VERSION ""

NS_ :

BS_:

BU_: GW TBOX VCU IPU DCDC OBC TESTER BMSH Vector_XXX
VAL_TABLE_ ABS_VehicleSpeedInvalid 1 "invalid" 0 "valid" ;
VAL_TABLE_ VCU_ePTReady 1 "PTReady  Active" 0 "PTReady Not Active" ;

BO_ 3221225472 VECTOR__INDEPENDENT_SIG_MSG: 0 Vector__XXX
 SG_ DCDC_InCurOver : 0|1@0+ (1,0) [0|1] "-" Vector__XXX
 SG_ DCDC_DataStorageFault : 0|1@0+ (1,0) [0|1] "-" Vector__XXX
 SG_ DCDC_InternalComFault : 0|1@0+ (1,0) [0|1] "-" Vector__XXX
 SG_ DCDC_BatVoltFault : 0|1@0+ (1,0) [0|1] "-" Vector__XXX
 SG_ DCDC_OutInversed : 0|1@0+ (1,0) [0|1] "-" Vector__XXX
 SG_ IPU_IPUTempSensorFault : 0|1@0+ (1,0) [0|1] "-" Vector__XXX
 SG_ IPU_5VUnderVoltageAlarm : 0|1@0+ (1,0) [0|1] "-" Vector__XXX
 SG_ IPU_5VOverVoltageAlarm : 0|1@0+ (1,0) [0|1] "-" Vector__XXX
 SG_ IPU_HVShortCircuit : 0|1@0+ (1,0) [0|1] "-" Vector__XXX
 SG_ IPU_IPUDrvModuleUV : 0|1@0+ (1,0) [0|1] "-" Vector__XXX
 SG_ IPU_MotModuleFault : 0|1@0+ (1,0) [0|1] "-" Vector__XXX

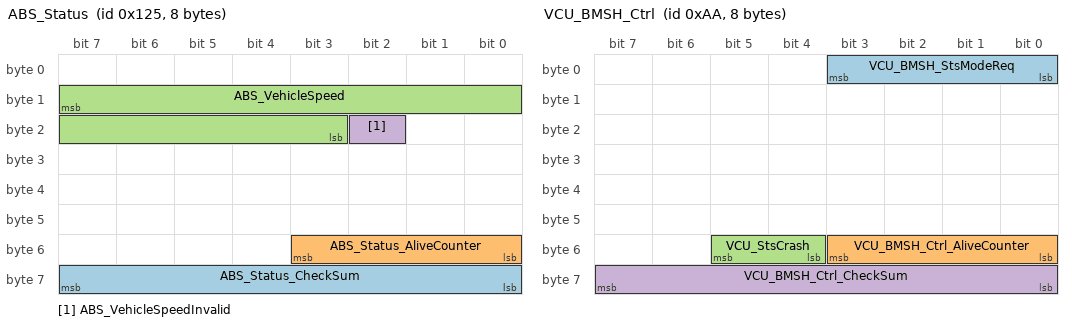
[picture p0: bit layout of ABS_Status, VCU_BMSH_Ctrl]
BO_ 293 ABS_Status: 8 GW
 SG_ ABS_Status_CheckSum : 63|8@0+ (1,0) [0|0] ""  BMSH,DCDC,IPU,OBC
 SG_ ABS_Status_AliveCounter : 51|4@0+ (1,0) [0|0] ""  BMSH,DCDC,IPU,OBC
 SG_ ABS_VehicleSpeed : 15|13@0- (0.05625,0) [0|460.63125] "kph"  BMSH,DCDC,IPU,OBC
 SG_ ABS_VehicleSpeedInvalid : 18|1@0- (1,0) [0|1] ""  BMSH,DCDC,IPU,OBC

BO_ 354 VCU_Ctrl: 8 GW
 SG_ VCU_ePTReady : 31|1@0+ (1,0) [0|1] "" Vector__XXX

BO_ 170 VCU_BMSH_Ctrl: 8 VCU
 SG_ VCU_BMSH_StsModeReq : 3|4@0+ (1,0) [0|15] "-"  BMSH
 SG_ VCU_BMSH_Ctrl_AliveCounter : 51|4@0+ (1,0) [0|15] "-"  BMSH
 SG_ VCU_StsCrash : 53|2@0+ (1,0) [0|1] "-"  BMSH
 SG_ VCU_BMSH_Ctrl_CheckSum : 63|8@0+ (1,0) [0|255] "-"  BMSH

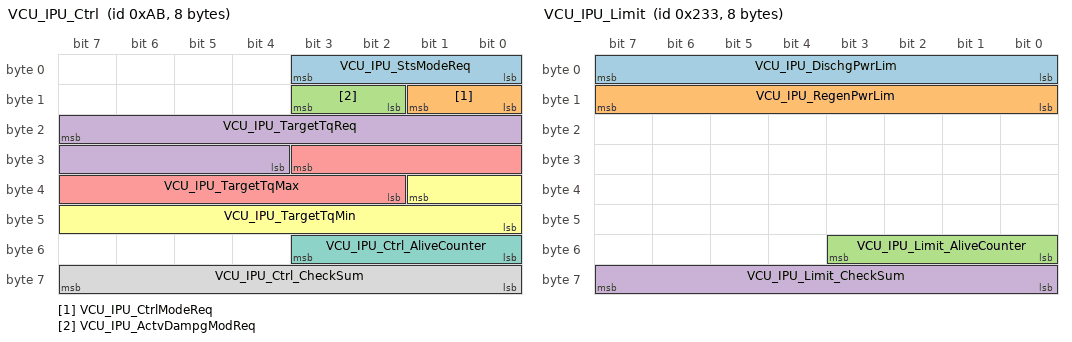
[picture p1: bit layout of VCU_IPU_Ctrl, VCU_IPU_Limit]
BO_ 171 VCU_IPU_Ctrl: 8 VCU
 SG_ VCU_IPU_StsModeReq : 3|4@0+ (1,0) [0|15] "-"  IPU
 SG_ VCU_IPU_CtrlModeReq : 9|2@0+ (1,0) [0|3] "-"  IPU
 SG_ VCU_IPU_ActvDampgModReq : 11|2@0+ (1,0) [0|3] "-"  IPU
 SG_ VCU_IPU_TargetTqReq : 23|12@0+ (0.5,-500) [-500|500] "Nm"  IPU
 SG_ VCU_IPU_TargetTqMax : 27|10@0+ (1,0) [0|500] "Nm"  IPU
 SG_ VCU_IPU_TargetTqMin : 33|10@0+ (1,-500) [-500|0] "Nm"  IPU
 SG_ VCU_IPU_Ctrl_AliveCounter : 51|4@0+ (1,0) [0|15] "-"  IPU
 SG_ VCU_IPU_Ctrl_CheckSum : 63|8@0+ (1,0) [0|255] "-"  IPU

BO_ 563 VCU_IPU_Limit: 8 VCU
 SG_ VCU_IPU_DischgPwrLim : 7|8@0+ (1,0) [0|250] "kW"  IPU
 SG_ VCU_IPU_RegenPwrLim : 15|8@0+ (1,0) [0|250] "kW"  IPU
 SG_ VCU_IPU_Limit_AliveCounter : 51|4@0+ (1,0) [0|15] "-"  IPU
 SG_ VCU_IPU_Limit_CheckSum : 63|8@0+ (1,0) [0|255] "-"  IPU

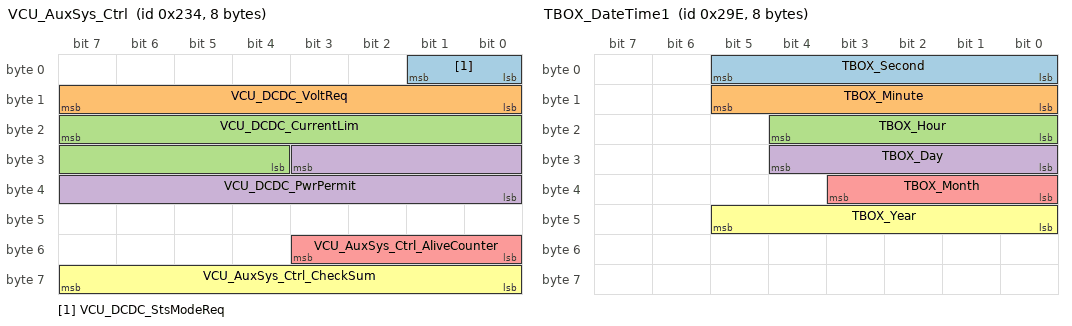
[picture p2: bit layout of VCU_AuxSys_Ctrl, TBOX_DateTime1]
BO_ 564 VCU_AuxSys_Ctrl: 8 VCU
 SG_ VCU_DCDC_StsModeReq : 1|2@0+ (1,0) [0|3] "-"  DCDC
 SG_ VCU_DCDC_VoltReq : 15|8@0+ (0.1,0) [0|25] "V"  DCDC
 SG_ VCU_DCDC_CurrentLim : 23|12@0+ (0.1,0) [0|250] "A"  DCDC
 SG_ VCU_DCDC_PwrPermit : 27|12@0+ (1,0) [0|3000] "Kw"  DCDC
 SG_ VCU_AuxSys_Ctrl_AliveCounter : 51|4@0+ (1,0) [0|15] "-"  DCDC
 SG_ VCU_AuxSys_Ctrl_CheckSum : 63|8@0+ (1,0) [0|255] "-"  DCDC

BO_ 569 VCU_Fault: 8 VCU
 SG_ VCU_ChgFaultReq : 3|4@0+ (1,0) [0|15] "-"  Vector_XXX
 SG_ VCU_DischgFaultReq : 7|4@0+ (1,0) [0|15] "-"  Vector_XXX

BO_ 257 PEPS_IMMOCode: 8 GW
 SG_ PEPS_IMMOCode : 7|64@0+ (1,0) [0|65535] "bit"  IPU

BO_ 482 PEPS_Message_Sts: 8 GW
 SG_ PEPS_PowerModeValidity : 1|2@0+ (1,0) [0|3] "bit"  BMSH,IPU
 SG_ PEPS_PowerMode : 4|3@0+ (1,0) [0|7] "bit"  BMSH,IPU

BO_ 645 BCM_LDoorWindowState: 8 GW
 SG_ BCM_DoorLockStatusDrv : 37|2@0+ (1,0) [0|3] "bit"  OBC

BO_ 670 TBOX_DateTime1: 8 TBOX
 SG_ TBOX_Second : 5|6@0+ (1,0) [0|59] "s"  BMSH
 SG_ TBOX_Minute : 13|6@0+ (1,0) [0|59] "m"  BMSH
 SG_ TBOX_Hour : 20|5@0+ (1,0) [0|23] "h"  BMSH
 SG_ TBOX_Day : 28|5@0+ (1,0) [1|31] "d"  BMSH
 SG_ TBOX_Month : 35|4@0+ (1,0) [1|12] "m"  BMSH
 SG_ TBOX_Year : 45|6@0+ (1,0) [0|63] "y"  BMSH

BO_ 1009 IPK_TotalOdometer: 8 GW
 SG_ IPK_IPKTotalOdometer : 7|24@0+ (0.1,0) [0|999999] "KM"  BMSH

BO_ 185 BMSH_Status: 8 BMSH
 SG_ BMSH_VCU_DischgFaultReq : 3|4@0+ (1,0) [0|15] "-"  VCU
 SG_ BMSH_StsDischgFault : 7|4@0+ (1,0) [0|15] "-"  Vector_XXX
 SG_ BMSH_VCU_ChgFaultReq : 11|4@0+ (1,0) [0|15] "-"  VCU
 SG_ BMSH_StsChgFault : 15|4@0+ (1,0) [0|15] "-"  Vector_XXX
 SG_ BMSH_StsCellBalance : 17|2@0+ (1,0) [0|3] "-"  TBOX
 SG_ BMSH_StsPrecharge : 19|2@0+ (1,0) [0|3] "-"  VCU
 SG_ BMSH_StsMode : 23|4@0+ (1,0) [0|15] "-"  IPU,VCU
 SG_ BMSH_VCU_StsMainHVIL : 25|2@0+ (1,0) [0|3] "-"  VCU
 SG_ BMSH_StsInsulation : 27|2@0+ (1,0) [0|3] "-"  VCU,TBOX
 SG_ BMSH_StsCC2 : 29|2@0+ (1,0) [0|3] "-"  VCU
 SG_ BMSH_StsCC1 : 31|2@0+ (1,0) [0|3] "-"  VCU
 SG_ BMSH_StsMainNegtiveRelay : 33|2@0+ (1,0) [0|3] "-"  VCU
 SG_ BMSH_StsMainPositiveRelay : 35|2@0+ (1,0) [0|3] "-"  IPU,VCU
 SG_ BMSH_VCU_StsDCChgRelay : 45|2@0+ (1,0) [0|3] "-"  VCU
 SG_ BMSH_VCU_StsPreChgRelay : 47|2@0+ (1,0) [0|3] "-"  VCU
 SG_ BMSH_Status_AliveCounter : 51|4@0+ (1,0) [0|15] "-"  IPU,VCU
 SG_ BMSH_VCU_Crash : 53|1@0+ (1,0) [0|1] "-"  VCU
 SG_ BMSH_Status_CheckSum : 63|8@0+ (1,0) [0|255] "-"  IPU,VCU

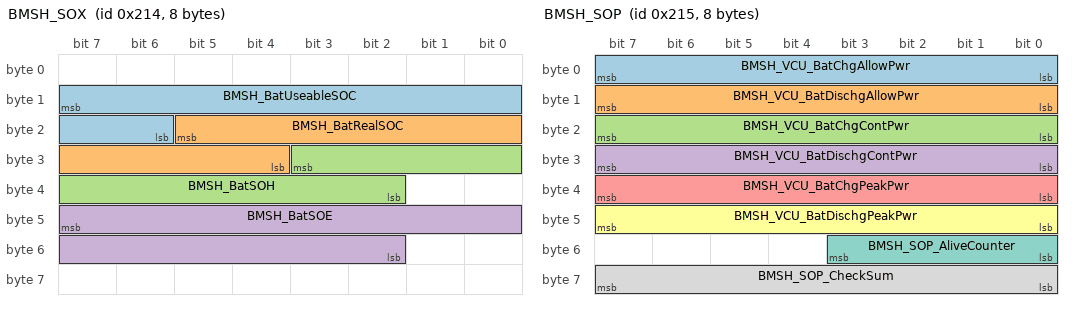
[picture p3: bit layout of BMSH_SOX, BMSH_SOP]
BO_ 532 BMSH_SOX: 8 BMSH
 SG_ BMSH_BatUseableSOC : 15|10@0+ (0.1,0) [0|100] "%"  VCU,TBOX
 SG_ BMSH_BatRealSOC : 21|10@0+ (0.1,0) [0|100] "%"  Vector_XXX
 SG_ BMSH_BatSOH : 27|10@0+ (0.1,0) [0|100] "%"  TBOX
 SG_ BMSH_BatSOE : 47|14@0+ (0.1,0) [0|999.9] "kWh"  VCU,TBOX

BO_ 533 BMSH_SOP: 8 BMSH
 SG_ BMSH_VCU_BatChgAllowPwr : 7|8@0+ (1,0) [0|250] "kW"  VCU
 SG_ BMSH_VCU_BatDischgAllowPwr : 15|8@0+ (1,0) [0|250] "kW"  VCU
 SG_ BMSH_VCU_BatChgContPwr : 23|8@0+ (1,0) [0|250] "kW"  VCU
 SG_ BMSH_VCU_BatDischgContPwr : 31|8@0+ (1,0) [0|250] "kW"  VCU
 SG_ BMSH_VCU_BatChgPeakPwr : 39|8@0+ (1,0) [0|250] "kW"  VCU
 SG_ BMSH_VCU_BatDischgPeakPwr : 47|8@0+ (1,0) [0|250] "kW"  VCU
 SG_ BMSH_SOP_AliveCounter : 51|4@0+ (1,0) [0|15] "-"  VCU
 SG_ BMSH_SOP_CheckSum : 63|8@0+ (1,0) [0|255] "-"  VCU

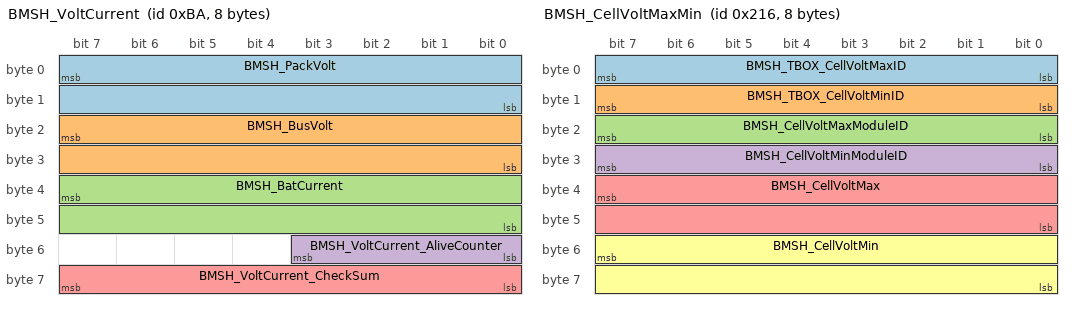
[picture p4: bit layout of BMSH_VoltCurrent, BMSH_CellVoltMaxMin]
BO_ 186 BMSH_VoltCurrent: 8 BMSH
 SG_ BMSH_PackVolt : 7|16@0+ (0.1,0) [0|1000] "V"  IPU,VCU,TBOX
 SG_ BMSH_BusVolt : 23|16@0+ (0.1,0) [0|1000] "V"  VCU
 SG_ BMSH_BatCurrent : 39|16@0+ (0.1,-1000) [-1000|1000] "A"  VCU,TBOX
 SG_ BMSH_VoltCurrent_AliveCounter : 51|4@0+ (1,0) [0|15] "-"  IPU,VCU
 SG_ BMSH_VoltCurrent_CheckSum : 63|8@0+ (1,0) [0|255] "-"  IPU,VCU

BO_ 534 BMSH_CellVoltMaxMin: 8 BMSH
 SG_ BMSH_TBOX_CellVoltMaxID : 7|8@0+ (1,0) [0|250] "-"  TBOX
 SG_ BMSH_TBOX_CellVoltMinID : 15|8@0+ (1,0) [0|250] "-"  TBOX
 SG_ BMSH_CellVoltMaxModuleID : 23|8@0+ (1,0) [0|250] "-"  TBOX
 SG_ BMSH_CellVoltMinModuleID : 31|8@0+ (1,0) [0|250] "-"  TBOX
 SG_ BMSH_CellVoltMax : 39|16@0+ (0.001,0) [0|5] "V"  VCU,TBOX
 SG_ BMSH_CellVoltMin : 55|16@0+ (0.001,0) [0|5] "V"  VCU,TBOX

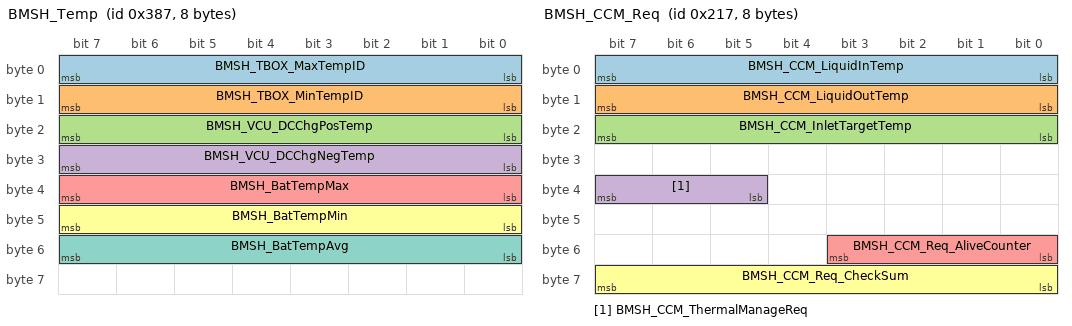
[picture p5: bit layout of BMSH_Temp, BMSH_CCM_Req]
BO_ 903 BMSH_Temp: 8 BMSH
 SG_ BMSH_TBOX_MaxTempID : 7|8@0+ (1,0) [0|250] "-"  TBOX
 SG_ BMSH_TBOX_MinTempID : 15|8@0+ (1,0) [0|250] "-"  TBOX
 SG_ BMSH_VCU_DCChgPosTemp : 23|8@0+ (1,-40) [-40|210] "℃"  VCU
 SG_ BMSH_VCU_DCChgNegTemp : 31|8@0+ (1,-40) [-40|210] "℃"  VCU
 SG_ BMSH_BatTempMax : 39|8@0+ (0.5,-40) [-40|87] "℃"  VCU,TBOX
 SG_ BMSH_BatTempMin : 47|8@0+ (0.5,-40) [-40|87] "℃"  VCU,TBOX
 SG_ BMSH_BatTempAvg : 55|8@0+ (0.5,-40) [-40|87] "℃"  OBC,VCU

BO_ 535 BMSH_CCM_Req: 8 BMSH
 SG_ BMSH_CCM_LiquidInTemp : 7|8@0+ (1,-40) [-40|255] "℃"  VCU
 SG_ BMSH_CCM_LiquidOutTemp : 15|8@0+ (1,-40) [-40|255] "℃"  VCU
 SG_ BMSH_CCM_InletTargetTemp : 23|8@0+ (1,-40) [-40|210] "℃"  VCU
 SG_ BMSH_CCM_ThermalManageReq : 39|3@0+ (1,0) [0|4] "-"  VCU
 SG_ BMSH_CCM_Req_AliveCounter : 51|4@0+ (1,0) [0|15] "-"  VCU
 SG_ BMSH_CCM_Req_CheckSum : 63|8@0+ (1,0) [0|255] "-"  VCU

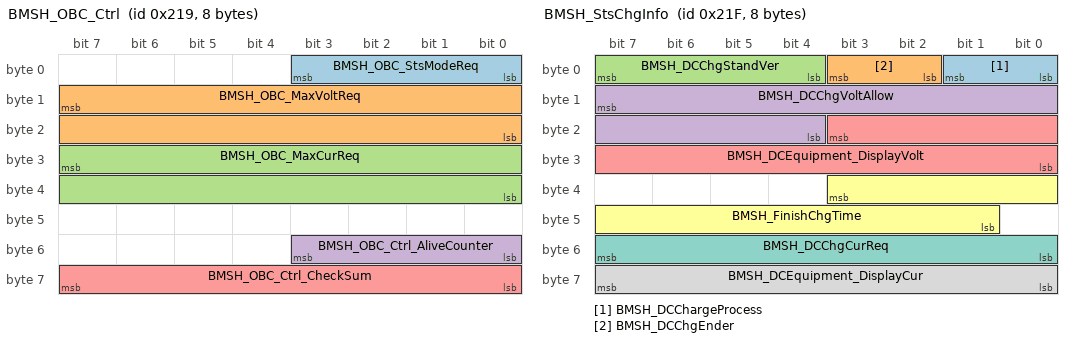
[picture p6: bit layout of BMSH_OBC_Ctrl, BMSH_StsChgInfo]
BO_ 537 BMSH_OBC_Ctrl: 8 BMSH
 SG_ BMSH_OBC_StsModeReq : 3|4@0+ (1,0) [0|15] "-"  OBC
 SG_ BMSH_OBC_MaxVoltReq : 15|16@0+ (0.1,0) [0|1000] "V"  OBC
 SG_ BMSH_OBC_MaxCurReq : 31|16@0+ (0.1,-1000) [-1000|1000] "A"  OBC
 SG_ BMSH_OBC_Ctrl_AliveCounter : 51|4@0+ (1,0) [0|15] "-"  OBC
 SG_ BMSH_OBC_Ctrl_CheckSum : 63|8@0+ (1,0) [0|255] "-"  OBC

BO_ 543 BMSH_StsChgInfo: 8 BMSH
 SG_ BMSH_DCChargeProcess : 1|2@0+ (1,0) [0|3] "-"  Vector_XXX
 SG_ BMSH_DCChgEnder : 3|2@0+ (1,0) [0|3] "-"  Vector_XXX
 SG_ BMSH_DCChgStandVer : 7|4@0+ (1,0) [0|15] "-"  Vector_XXX
 SG_ BMSH_DCChgVoltAllow : 15|12@0+ (1,0) [0|1000] "V"  Vector_XXX
 SG_ BMSH_DCEquipment_DisplayVolt : 19|12@0+ (1,0) [0|1000] "V"  Vector_XXX
 SG_ BMSH_FinishChgTime : 35|11@0+ (1,0) [0|1800] "Min"  VCU
 SG_ BMSH_DCChgCurReq : 55|8@0+ (1,0) [0|254] "A"  Vector_XXX
 SG_ BMSH_DCEquipment_DisplayCur : 63|8@0+ (1,0) [0|254] "A"  Vector_XXX

BO_ 904 BMSH_Fault: 8 BMSH
 SG_ BMSH_ChgOverCurrent : 1|2@0+ (1,0) [0|3] "-"  VCU
 SG_ BMSH_DisChgOverCurrent : 3|2@0+ (1,0) [0|3] "-"  Vector_XXX
 SG_ BMSH_CellOverVolt : 5|2@0+ (1,0) [0|3] "-"  Vector_XXX
 SG_ BMSH_CellUnderVolt : 7|2@0+ (1,0) [0|3] "-"  Vector_XXX
 SG_ BMSH_ChgOverTemp : 9|2@0+ (1,0) [0|3] "-"  Vector_XXX
 SG_ BMSH_BatUnderVolt : 11|2@0+ (1,0) [0|3] "-"  Vector_XXX
 SG_ BMSH_BatOverVolt : 13|2@0+ (1,0) [0|3] "-"  Vector_XXX
 SG_ BMSH_CellDiffVoltUniform : 15|2@0+ (1,0) [0|3] "-"  Vector_XXX
 SG_ BMSH_CellTempUniformity : 17|2@0+ (1,0) [0|3] "-"  Vector_XXX
 SG_ BMSH_DisChgUnderTemp : 19|2@0+ (1,0) [0|3] "-"  Vector_XXX
 SG_ BMSH_DisChgOverTemp : 21|2@0+ (1,0) [0|3] "-"  Vector_XXX
 SG_ BMSH_ChgUnderTemp : 23|2@0+ (1,0) [0|3] "-"  Vector_XXX
 SG_ BMSH_MainPosRelayFault : 25|2@0+ (1,0) [0|3] "-"  VCU,TBOX
 SG_ BMSH_RecoveryOverCurrent : 27|2@0+ (1,0) [0|3] "-"  Vector_XXX
 SG_ BMSH_BatUnderSOC : 29|2@0+ (1,0) [0|3] "-"  Vector_XXX
 SG_ BMSH_BatOverSOC : 31|2@0+ (1,0) [0|3] "-"  Vector_XXX
 SG_ BMSH_DCChgPlugNOverTemp : 33|2@0+ (1,0) [0|3] "-"  Vector_XXX
 SG_ BMSH_DCChgPlugPOverTemp : 35|2@0+ (1,0) [0|3] "-"  Vector_XXX
 SG_ BMSH_DCChgRelayFault : 37|2@0+ (1,0) [0|3] "-"  TBOX
 SG_ BMSH_MainNegRelayFault : 39|2@0+ (1,0) [0|3] "-"  VCU,TBOX
 SG_ BMSH_IntComFault : 40|1@0+ (1,0) [0|1] "-"  Vector_XXX
 SG_ BMSH_DisChgComFault : 41|1@0+ (1,0) [0|1] "-"  Vector_XXX
 SG_ BMSH_FastChgComFault : 42|1@0+ (1,0) [0|1] "-"  Vector_XXX
 SG_ BMSH_12VBatFault : 43|1@0+ (1,0) [0|1] "-"  Vector_XXX
 SG_ BMSH_ConnectPosOverTemp : 45|2@0+ (1,0) [0|3] "-"  VCU
 SG_ BMSH_ConnectNegOverTemp : 47|2@0+ (1,0) [0|3] "-"  VCU
 SG_ BMSH_VCUChksumFault : 50|1@0+ (1,0) [0|1] "-"  Vector_XXX
 SG_ BMSH_VCURollCountFault : 51|1@0+ (1,0) [0|1] "-"  Vector_XXX
 SG_ BMSH_OBCChksumFault : 52|1@0+ (1,0) [0|1] "-"  Vector_XXX
 SG_ BMSH_OBCRollCountFault : 53|1@0+ (1,0) [0|1] "-"  Vector_XXX
 SG_ BMSH_SelfCheckFault : 54|1@0+ (1,0) [0|1] "-"  Vector_XXX
 SG_ BMSH_DataStorageFault : 55|1@0+ (1,0) [0|1] "-"  Vector_XXX
 SG_ BMSH_FaultCode : 63|8@0+ (1,0) [0|255] "-"  Vector_XXX

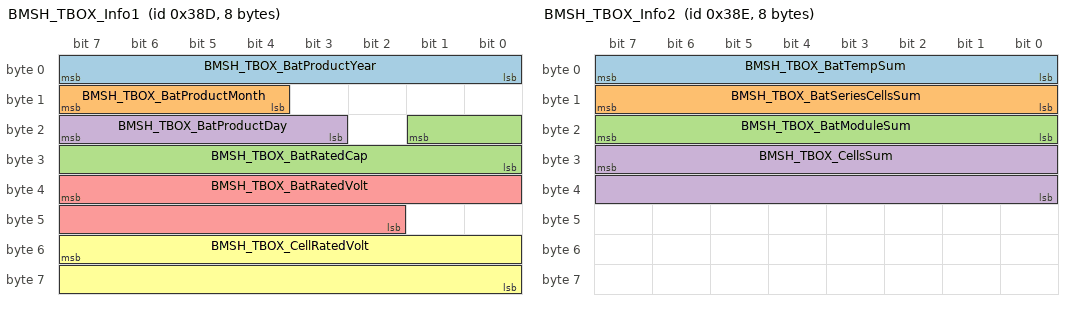
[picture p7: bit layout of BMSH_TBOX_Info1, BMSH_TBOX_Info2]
BO_ 909 BMSH_TBOX_Info1: 8 BMSH
 SG_ BMSH_TBOX_BatProductYear : 7|8@0+ (1,2000) [2000|2250] "-"  TBOX
 SG_ BMSH_TBOX_BatProductMonth : 15|4@0+ (1,0) [1|12] "-"  TBOX
 SG_ BMSH_TBOX_BatRatedCap : 17|10@0+ (0.1,0) [0|100] "kWh"  TBOX
 SG_ BMSH_TBOX_BatProductDay : 23|5@0+ (1,0) [1|31] "-"  TBOX
 SG_ BMSH_TBOX_BatRatedVolt : 39|14@0+ (0.1,0) [0|1000] "V"  TBOX
 SG_ BMSH_TBOX_CellRatedVolt : 55|16@0+ (0.001,0) [0|5] "V"  TBOX

BO_ 910 BMSH_TBOX_Info2: 8 BMSH
 SG_ BMSH_TBOX_BatTempSum : 7|8@0+ (1,0) [0|250] "-"  TBOX
 SG_ BMSH_TBOX_BatSeriesCellsSum : 15|8@0+ (1,0) [0|250] "-"  TBOX
 SG_ BMSH_TBOX_BatModuleSum : 23|8@0+ (1,0) [0|250] "-"  TBOX
 SG_ BMSH_TBOX_CellsSum : 31|16@0+ (1,0) [0|65531] "-"  TBOX

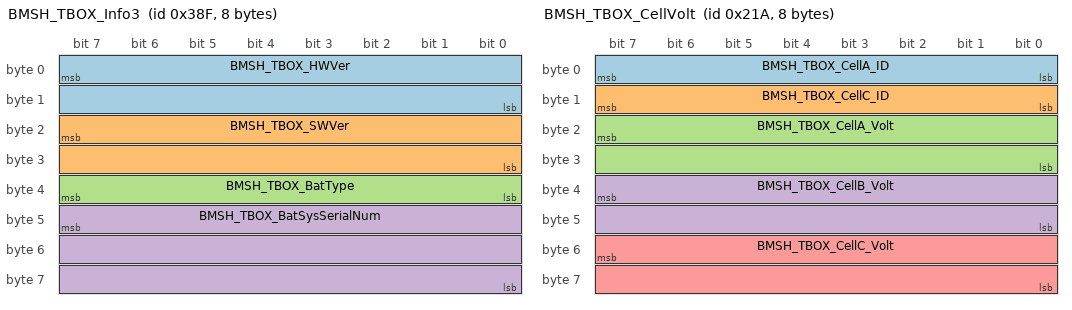
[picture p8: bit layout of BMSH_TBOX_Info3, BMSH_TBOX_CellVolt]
BO_ 911 BMSH_TBOX_Info3: 8 BMSH
 SG_ BMSH_TBOX_HWVer : 7|16@0+ (1,0) [0|65535] "-"  TBOX
 SG_ BMSH_TBOX_SWVer : 23|16@0+ (1,0) [0|65535] "-"  TBOX
 SG_ BMSH_TBOX_BatType : 39|8@0+ (1,0) [0|255] "-"  TBOX
 SG_ BMSH_TBOX_BatSysSerialNum : 47|24@0+ (1,0) [0|999999] "-"  TBOX

BO_ 538 BMSH_TBOX_CellVolt: 8 BMSH
 SG_ BMSH_TBOX_CellA_ID : 7|8@0+ (1,0) [0|210] "-"  TBOX
 SG_ BMSH_TBOX_CellC_ID : 15|8@0+ (1,0) [0|210] "-"  TBOX
 SG_ BMSH_TBOX_CellA_Volt : 23|16@0+ (0.001,0) [0|5] "V"  TBOX
 SG_ BMSH_TBOX_CellB_Volt : 39|16@0+ (0.001,0) [0|5] "V"  TBOX
 SG_ BMSH_TBOX_CellC_Volt : 55|16@0+ (0.001,0) [0|5] "V"  TBOX

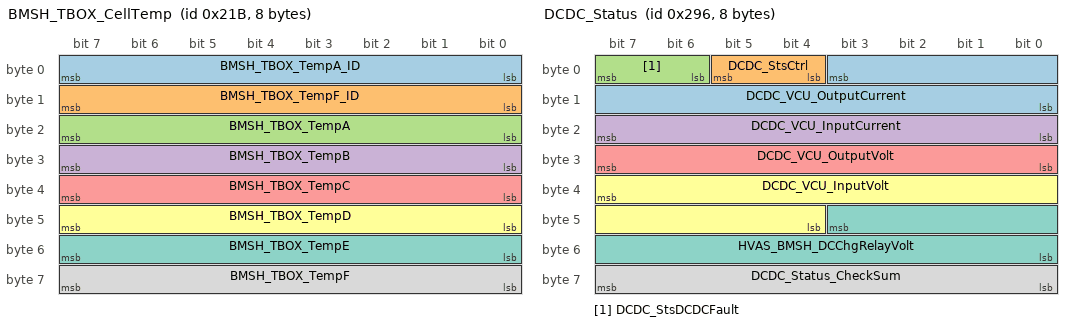
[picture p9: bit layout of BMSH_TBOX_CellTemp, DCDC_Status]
BO_ 539 BMSH_TBOX_CellTemp: 8 BMSH
 SG_ BMSH_TBOX_TempA_ID : 7|8@0+ (1,0) [0|210] "-"  TBOX
 SG_ BMSH_TBOX_TempF_ID : 15|8@0+ (1,0) [0|210] "-"  TBOX
 SG_ BMSH_TBOX_TempA : 23|8@0+ (0.5,-40) [-40|87] "℃"  TBOX
 SG_ BMSH_TBOX_TempB : 31|8@0+ (0.5,-40) [-40|87] "℃"  TBOX
 SG_ BMSH_TBOX_TempC : 39|8@0+ (0.5,-40) [-40|87] "℃"  TBOX
 SG_ BMSH_TBOX_TempD : 47|8@0+ (0.5,-40) [-40|87] "℃"  TBOX
 SG_ BMSH_TBOX_TempE : 55|8@0+ (0.5,-40) [-40|87] "℃"  TBOX
 SG_ BMSH_TBOX_TempF : 63|8@0+ (0.5,-40) [-40|87] "℃"  TBOX

BO_ 905 BMSH_TBOX_Fault: 8 BMSH
 SG_ BMSH_TBOX_BatFaultList : 7|16@0+ (1,0) [0|250] "-"  TBOX
 SG_ BMSH_TBOX_BatOverTemp : 16|1@0+ (1,0) [0|1] "-"  TBOX
 SG_ BMSH_TBOX_BatLowTemp : 17|1@0+ (1,0) [0|1] "-"  TBOX
 SG_ BMSH_TBOX_BatOverVoltage : 18|1@0+ (1,0) [0|1] "-"  TBOX
 SG_ BMSH_TBOX_BatUnderVoltage : 19|1@0+ (1,0) [0|1] "-"  TBOX
 SG_ BMSH_TBOX_BatStoreSysFault : 20|1@0+ (1,0) [0|1] "-"  TBOX
 SG_ BMSH_TBOX_BatIsoAlarm : 21|1@0+ (1,0) [0|1] "-"  TBOX
 SG_ BMSH_TBOX_BatHVILFault : 22|1@0+ (1,0) [0|1] "-"  TBOX
 SG_ BMSH_TBOX_BatMismatching : 23|1@0+ (1,0) [0|1] "-"  TBOX
 SG_ BMSH_TBOX_CellOverVoltage : 24|1@0+ (1,0) [0|1] "-"  TBOX
 SG_ BMSH_TBOX_CellUnderVoltage : 25|1@0+ (1,0) [0|1] "-"  TBOX
 SG_ BMSH_TBOX_BatUniformity : 26|1@0+ (1,0) [0|1] "-"  TBOX
 SG_ BMSH_TBOX_BatOverCharge : 27|1@0+ (1,0) [0|1] "-"  TBOX
 SG_ BMSH_TBOX_SOCHop : 28|1@0+ (1,0) [0|1] "-"  TBOX
 SG_ BMSH_TBOX_BatOverSOC : 29|1@0+ (1,0) [0|1] "-"  TBOX
 SG_ BMSH_TBOX_BatLowSOC : 30|1@0+ (1,0) [0|1] "-"  TBOX
 SG_ BMSH_TBOX_BatTempUniformity : 31|1@0+ (1,0) [0|1] "-"  TBOX
 SG_ BMSH_DCChgRx_OTime_CSD : 33|1@0+ (1,0) [0|1] "-"  Vector_XXX
 SG_ BMSH_DCChgRx_OTime_CCS : 34|1@0+ (1,0) [0|1] "-"  Vector_XXX
 SG_ BMSH_DCChgRx_OTime_CROAA : 35|1@0+ (1,0) [0|1] "-"  Vector_XXX
 SG_ BMSH_DCChgRx_OTime_CRO00 : 36|1@0+ (1,0) [0|1] "-"  Vector_XXX
 SG_ BMSH_DCChgRx_OTime_CML : 37|1@0+ (1,0) [0|1] "-"  Vector_XXX
 SG_ BMSH_DCChgRx_OTime_CRMAA : 38|1@0+ (1,0) [0|1] "-"  Vector_XXX
 SG_ BMSH_DCChgRx_OTime_CRM00 : 39|1@0+ (1,0) [0|1] "-"  Vector_XXX
 SG_ BMSH_TBOX_InsulationResistance : 55|16@0+ (1,0) [0|60000] "KΩ"  TBOX

BO_ 662 DCDC_Status: 8 DCDC
 SG_ DCDC_VCU_OutputCurrent : 3|12@0+ (0.1,0) [0|250] "A"  VCU
 SG_ DCDC_StsCtrl : 5|2@0+ (1,0) [0|3] "-"  TBOX,VCU
 SG_ DCDC_StsDCDCFault : 7|2@0+ (1,0) [0|3] "-"  TBOX,VCU
 SG_ DCDC_VCU_InputCurrent : 23|8@0+ (0.1,0) [0|25] "A"  VCU
 SG_ DCDC_VCU_OutputVolt : 31|8@0+ (0.1,0) [0|25] "V"  VCU
 SG_ DCDC_VCU_InputVolt : 39|12@0+ (0.5,0) [0|1000] "V"  VCU
 SG_ HVAS_BMSH_DCChgRelayVolt : 43|12@0+ (0.5,0) [0|1000] "V"  BMSH
 SG_ DCDC_Status_CheckSum : 63|8@0+ (1,0) [0|255] "-"  VCU

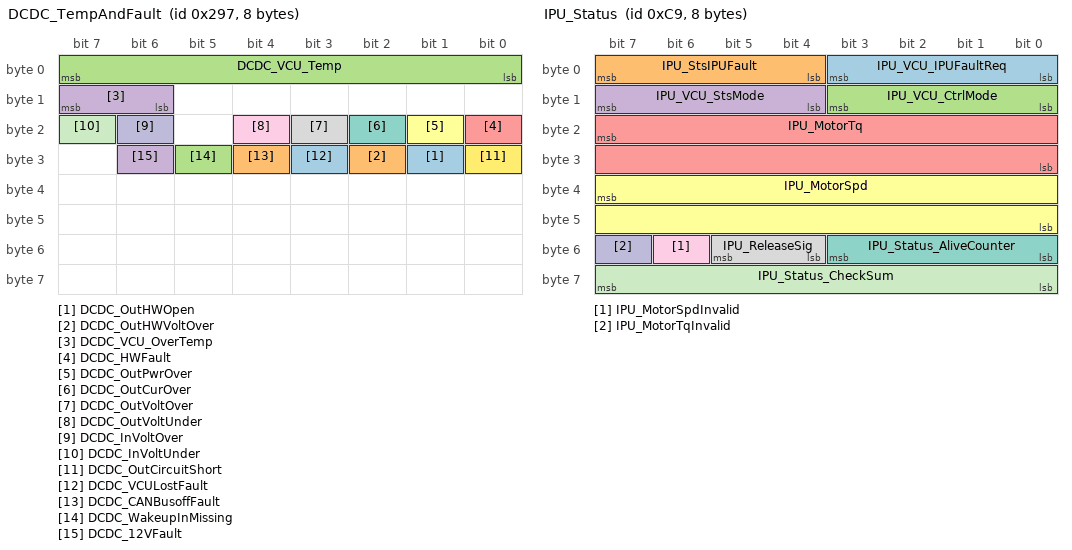
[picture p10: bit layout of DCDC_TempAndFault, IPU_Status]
BO_ 663 DCDC_TempAndFault: 8 DCDC
 SG_ DCDC_OutHWOpen : 25|1@0+ (1,0) [0|1] "" Vector__XXX
 SG_ DCDC_OutHWVoltOver : 26|1@0+ (1,0) [0|1] "" Vector__XXX
 SG_ DCDC_VCU_Temp : 7|8@0+ (1,-40) [-40|210] "℃"  VCU
 SG_ DCDC_VCU_OverTemp : 15|2@0+ (1,0) [0|3] "-"  TBOX,VCU
 SG_ DCDC_HWFault : 16|1@0+ (1,0) [0|1] "-"  Vector_XXX
 SG_ DCDC_OutPwrOver : 17|1@0+ (1,0) [0|1] "-"  Vector_XXX
 SG_ DCDC_OutCurOver : 18|1@0+ (1,0) [0|1] "-"  Vector_XXX
 SG_ DCDC_OutVoltOver : 19|1@0+ (1,0) [0|1] "-"  Vector_XXX
 SG_ DCDC_OutVoltUnder : 20|1@0+ (1,0) [0|1] "-"  Vector_XXX
 SG_ DCDC_InVoltOver : 22|1@0+ (1,0) [0|1] "-"  Vector_XXX
 SG_ DCDC_InVoltUnder : 23|1@0+ (1,0) [0|1] "-"  Vector_XXX
 SG_ DCDC_OutCircuitShort : 24|1@0+ (1,0) [0|1] "-"  Vector_XXX
 SG_ DCDC_VCULostFault : 27|1@0+ (1,0) [0|1] "-"  Vector_XXX
 SG_ DCDC_CANBusoffFault : 28|1@0+ (1,0) [0|1] "-"  Vector_XXX
 SG_ DCDC_WakeupInMissing : 29|1@0+ (1,0) [0|1] "-"  Vector_XXX
 SG_ DCDC_12VFault : 30|1@0+ (1,0) [0|1] "-"  Vector_XXX

BO_ 201 IPU_Status: 8 IPU
 SG_ IPU_VCU_IPUFaultReq : 3|4@0+ (1,0) [0|15] "-"  VCU
 SG_ IPU_StsIPUFault : 7|4@0+ (1,0) [0|15] "-"  Vector_XXX
 SG_ IPU_VCU_CtrlMode : 11|4@0+ (1,0) [0|15] "-"  VCU
 SG_ IPU_VCU_StsMode : 15|4@0+ (1,0) [0|15] "-"  VCU
 SG_ IPU_MotorTq : 23|16@0+ (0.1,-1200) [-1200|1022] "Nm"  TBOX,VCU
 SG_ IPU_MotorSpd : 39|16@0+ (1,-20000) [-20000|45531] "rpm"  TBOX,VCU
 SG_ IPU_Status_AliveCounter : 51|4@0+ (1,0) [0|15] "-"  VCU
 SG_ IPU_ReleaseSig : 53|2@0+ (1,0) [0|3] "-"  VCU
 SG_ IPU_MotorSpdInvalid : 54|1@0+ (1,0) [0|1] "-"  VCU
 SG_ IPU_MotorTqInvalid : 55|1@0+ (1,0) [0|1] "-"  VCU
 SG_ IPU_Status_CheckSum : 63|8@0+ (1,0) [0|255] "-"  VCU

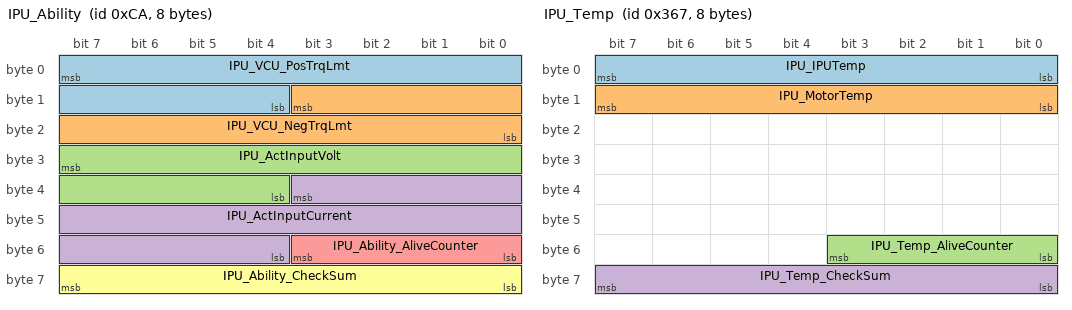
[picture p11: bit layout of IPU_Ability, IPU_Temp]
BO_ 202 IPU_Ability: 8 IPU
 SG_ IPU_VCU_PosTrqLmt : 7|12@0+ (0.1,0) [0|400] "Nm"  VCU
 SG_ IPU_VCU_NegTrqLmt : 11|12@0+ (0.1,-400) [-400|0] "Nm"  VCU
 SG_ IPU_ActInputVolt : 31|12@0+ (0.5,0) [0|1000] "V"  BMSH,TBOX,VCU
 SG_ IPU_ActInputCurrent : 35|16@0+ (0.1,-1000) [-1000|1000] "A"  BMSH,TBOX,VCU
 SG_ IPU_Ability_AliveCounter : 51|4@0+ (1,0) [0|15] "-"  VCU
 SG_ IPU_Ability_CheckSum : 63|8@0+ (1,0) [0|255] "-"  VCU

BO_ 871 IPU_Temp: 8 IPU
 SG_ IPU_IPUTemp : 7|8@0+ (1,-40) [-40|210] "℃"  VCU,TBOX
 SG_ IPU_MotorTemp : 15|8@0+ (1,-40) [-40|210] "℃"  VCU,TBOX
 SG_ IPU_Temp_AliveCounter : 51|4@0+ (1,0) [0|15] "-"  VCU
 SG_ IPU_Temp_CheckSum : 63|8@0+ (1,0) [0|255] "-"  VCU

BO_ 872 IPU_Fault: 8 IPU
 SG_ IPU_TheftFault : 48|1@0+ (1,0) [0|1] "" Vector__XXX
 SG_ IPU_NoESK : 49|1@0+ (1,0) [0|1] "" Vector__XXX
 SG_ IPU_InitMode : 50|1@0+ (1,0) [0|1] "" Vector__XXX
 SG_ IPU_IPUCurrentSenVZeroFault : 43|1@0+ (1,0) [0|1] "" Vector__XXX
 SG_ IPU_IPUCurrentSenUZeroFault : 44|1@0+ (1,0) [0|1] "" Vector__XXX
 SG_ IPU_MotTempSenVFault : 3|1@0+ (1,0) [0|1] "" Vector__XXX
 SG_ IPU_MotTempSenWFault : 45|1@0+ (1,0) [0|1] "" Vector__XXX
 SG_ IPU_PhaseOverCurrentSWFault : 0|1@0+ (1,0) [0|1] "" Vector__XXX
 SG_ IPU_IPUOverTempFault : 1|1@0+ (1,0) [0|1] "-"  VCU
 SG_ IPU_IPUOverTempAlarm : 2|1@0+ (1,0) [0|1] "-"  VCU,TBOX
 SG_ IPU_MotTempSenUFault : 4|1@0+ (1,0) [0|1] "-"  Vector_XXX
 SG_ IPU_MotTempSenFault : 5|1@0+ (1,0) [0|1] "-"  Vector_XXX
 SG_ IPU_MotOverTempFault : 6|1@0+ (1,0) [0|1] "-"  VCU
 SG_ IPU_MotOverTempAlarm : 7|1@0+ (1,0) [0|1] "-"  VCU,TBOX
 SG_ IPU_HVUnderVoltage2 : 8|1@0+ (1,0) [0|1] "-"  Vector_XXX
 SG_ IPU_HVUnderVoltage1 : 9|1@0+ (1,0) [0|1] "-"  Vector_XXX
 SG_ IPU_HVOverVoltage2 : 10|1@0+ (1,0) [0|1] "-"  Vector_XXX
 SG_ IPU_HVOverVoltage1 : 11|1@0+ (1,0) [0|1] "-"  Vector_XXX
 SG_ IPU_IPUCPhsSenRatFault : 12|1@0+ (1,0) [0|1] "-"  Vector_XXX
 SG_ IPU_IPUAPhsSenRatFault : 14|1@0+ (1,0) [0|1] "-"  Vector_XXX
 SG_ IPU_PhaseOverCurrentHWFault : 15|1@0+ (1,0) [0|1] "-"  Vector_XXX
 SG_ IPU_MotOverSpd2 : 16|1@0+ (1,0) [0|1] "-"  VCU,TBOX
 SG_ IPU_MotOverSpd1 : 17|1@0+ (1,0) [0|1] "-"  VCU,TBOX
 SG_ IPU_12VUnderVoltageAlarm : 20|1@0+ (1,0) [0|1] "-"  Vector_XXX
 SG_ IPU_12VOverVoltageAlarm : 21|1@0+ (1,0) [0|1] "-"  Vector_XXX
 SG_ IPU_IPUHVSensorFault : 22|1@0+ (1,0) [0|1] "-"  Vector_XXX
 SG_ IPU_IPUDisChgFault : 24|1@0+ (1,0) [0|1] "-"  Vector_XXX
 SG_ IPU_IPUEnableFault : 26|1@0+ (1,0) [0|1] "-"  Vector_XXX
 SG_ IPU_MotTrqChksumFault : 27|1@0+ (1,0) [0|1] "-"  Vector_XXX
 SG_ IPU_MotTrqLimFault : 28|1@0+ (1,0) [0|1] "-"  Vector_XXX
 SG_ IPU_MotTrqFault : 29|1@0+ (1,0) [0|1] "-"  Vector_XXX
 SG_ IPU_IPUBlockedFault : 30|1@0+ (1,0) [0|1] "-"  Vector_XXX
 SG_ IPU_MotRotSenFault : 31|1@0+ (1,0) [0|1] "-"  Vector_XXX
 SG_ IPU_BMSHLostFault : 34|1@0+ (1,0) [0|1] "-"  Vector_XXX
 SG_ IPU_VCULostFault : 35|1@0+ (1,0) [0|1] "-"  Vector_XXX
 SG_ IPU_CANBusoffFault : 36|1@0+ (1,0) [0|1] "-"  Vector_XXX
 SG_ IPU_IGBTDrvPwrFault : 37|1@0+ (1,0) [0|1] "-"  Vector_XXX
 SG_ IPU_IPUFaultCode : 63|8@0+ (1,0) [0|255] "-"  Vector_XXX

BO_ 256 IPU_Auth: 8 IPU
 SG_ IPU_BCM_Auth : 7|64@0+ (1,0) [0|65535] "-"  GW

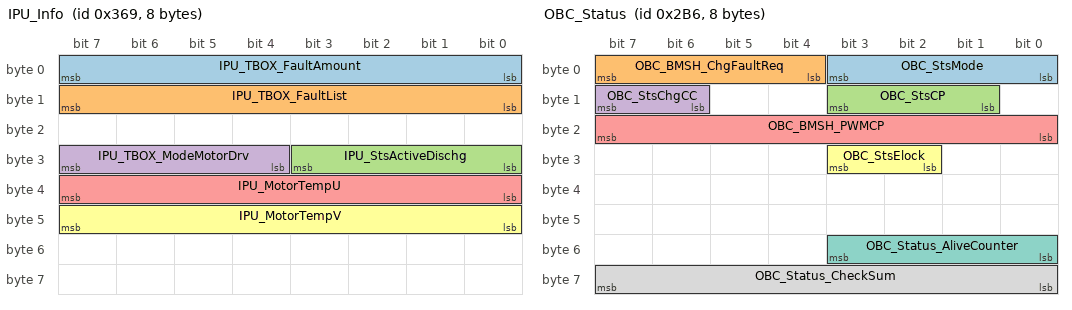
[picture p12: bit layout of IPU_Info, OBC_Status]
BO_ 873 IPU_Info: 8 IPU
 SG_ IPU_TBOX_FaultAmount : 7|8@0+ (1,0) [0|255] "-"  TBOX
 SG_ IPU_TBOX_FaultList : 15|8@0+ (1,0) [0|255] "-"  TBOX
 SG_ IPU_StsActiveDischg : 27|4@0+ (1,0) [0|15] "-"  BMSH,VCU
 SG_ IPU_TBOX_ModeMotorDrv : 31|4@0+ (1,0) [0|15] "-"  TBOX
 SG_ IPU_MotorTempU : 39|8@0+ (1,-40) [-40|210] "℃"  Vector_XXX
 SG_ IPU_MotorTempV : 47|8@0+ (1,-40) [-40|210] "℃"  Vector_XXX

BO_ 694 OBC_Status: 8 OBC
 SG_ OBC_StsMode : 3|4@0+ (1,0) [0|15] "-"  BMSH,VCU
 SG_ OBC_BMSH_ChgFaultReq : 7|4@0+ (1,0) [0|15] "-"  BMSH,VCU
 SG_ OBC_StsCP : 11|3@0+ (1,0) [0|7] "-"  BMSH,VCU
 SG_ OBC_StsChgCC : 15|2@0+ (1,0) [0|3] "-"  BMSH,VCU
 SG_ OBC_BMSH_PWMCP : 23|8@0+ (0.4,0) [0|100] "%"  BMSH
 SG_ OBC_StsElock : 27|2@0+ (1,0) [0|3] "-"  BMSH,VCU
 SG_ OBC_Status_AliveCounter : 51|4@0+ (1,0) [0|15] "-"  BMSH,VCU
 SG_ OBC_Status_CheckSum : 63|8@0+ (1,0) [0|255] "-"  BMSH,VCU

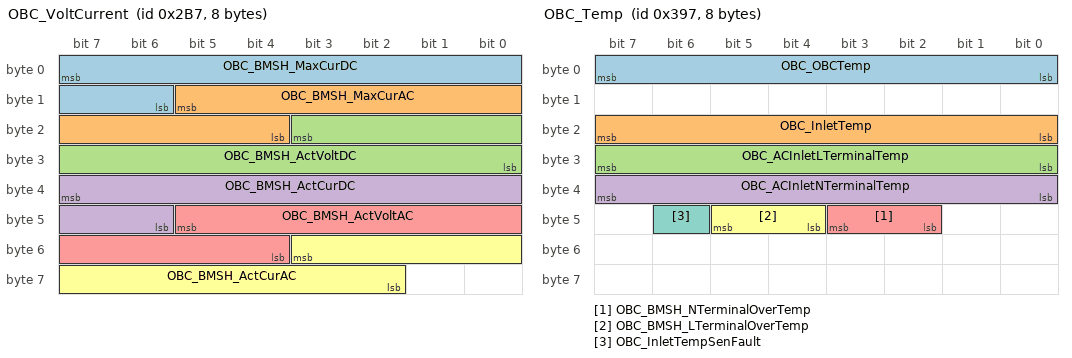
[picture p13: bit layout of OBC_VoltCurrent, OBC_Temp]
BO_ 695 OBC_VoltCurrent: 8 OBC
 SG_ OBC_BMSH_MaxCurDC : 7|10@0+ (0.1,0) [0|100] "A"  BMSH
 SG_ OBC_BMSH_MaxCurAC : 13|10@0+ (0.1,0) [0|100] "A"  BMSH
 SG_ OBC_BMSH_ActVoltDC : 19|12@0+ (0.5,0) [0|1000] "V"  BMSH
 SG_ OBC_BMSH_ActCurDC : 39|10@0+ (0.1,0) [0|100] "A"  BMSH
 SG_ OBC_BMSH_ActVoltAC : 45|10@0+ (0.5,0) [0|500] "V"  BMSH
 SG_ OBC_BMSH_ActCurAC : 51|10@0+ (0.1,0) [0|100] "A"  BMSH

BO_ 919 OBC_Temp: 8 OBC
 SG_ OBC_OBCTemp : 7|8@0+ (1,-40) [-40|214] "℃"  VCU
 SG_ OBC_InletTemp : 23|8@0+ (1,-40) [-40|210] "℃"  VCU
 SG_ OBC_ACInletLTerminalTemp : 31|8@0+ (1,-40) [-40|210] "℃"  BMSH,VCU
 SG_ OBC_ACInletNTerminalTemp : 39|8@0+ (1,-40) [-40|210] "℃"  BMSH,VCU
 SG_ OBC_BMSH_NTerminalOverTemp : 43|2@0+ (1,0) [0|3] "-"  BMSH
 SG_ OBC_BMSH_LTerminalOverTemp : 45|2@0+ (1,0) [0|3] "-"  BMSH
 SG_ OBC_InletTempSenFault : 46|1@0+ (1,0) [0|1] "-"  VCU

BO_ 920 OBC_Fault: 8 OBC
 SG_ OBC_InputACinterrupt : 0|1@0+ (1,0) [0|1] "-"  Vector_XXX
 SG_ OBC_InputOverCurrent : 1|1@0+ (1,0) [0|1] "-"  Vector_XXX
 SG_ OBC_InputOverVoltage : 2|1@0+ (1,0) [0|1] "-"  Vector_XXX
 SG_ OBC_InputUnderVoltage : 3|1@0+ (1,0) [0|1] "-"  Vector_XXX
 SG_ OBC_12VFault : 4|1@0+ (1,0) [0|1] "-"  Vector_XXX
 SG_ OBC_S2ControlFault : 5|1@0+ (1,0) [0|1] "-"  Vector_XXX
 SG_ OBC_OverTemp : 7|2@0+ (1,0) [0|3] "-"  Vector_XXX
 SG_ OBC_ComTimeOut : 8|1@0+ (1,0) [0|1] "-"  Vector_XXX
 SG_ OBC_WakeUpInputMiss : 9|1@0+ (1,0) [0|1] "-"  Vector_XXX
 SG_ OBC_BatteryVoltageFault : 10|1@0+ (1,0) [0|1] "-"  Vector_XXX
 SG_ OBC_OutputInversed : 11|1@0+ (1,0) [0|1] "-"  Vector_XXX
 SG_ OBC_OutputShortCircuit : 12|1@0+ (1,0) [0|1] "-"  Vector_XXX
 SG_ OBC_OutputOverCurrent : 13|1@0+ (1,0) [0|1] "-"  Vector_XXX
 SG_ OBC_OutputOverVoltage : 14|1@0+ (1,0) [0|1] "-"  Vector_XXX
 SG_ OBC_OutputUnderVoltage : 15|1@0+ (1,0) [0|1] "-"  Vector_XXX
 SG_ OBC_InternalComFault : 20|1@0+ (1,0) [0|1] "-"  Vector_XXX
 SG_ OBC_DataStorageFault : 21|1@0+ (1,0) [0|1] "-"  Vector_XXX
 SG_ OBC_HWFault : 22|1@0+ (1,0) [0|1] "-"  Vector_XXX
 SG_ OBC_ComMissing : 23|1@0+ (1,0) [0|1] "-"  Vector_XXX

BO_ 2015 Func_DiagReq: 8 TESTER

BO_ 2022 VCU_OBD_DiagReq: 8 TESTER

BO_ 2030 VCU_OBD_DiagResp: 8 VCU

BO_ 2019 IPU_DiagReq: 8 TESTER

BO_ 2027 IPU_DiagResp: 8 IPU

BO_ 1972 DCDC_DiagReq: 8 TESTER

BO_ 1980 DCDC_DiagResp: 8 DCDC

BO_ 2023 OBC_DiagReq: 8 TESTER

BO_ 2031 OBC_DiagResp: 8 OBC

BO_ 2018 BMSH_DiagReq: 8 TESTER

BO_ 2026 BMSH_DiagResp: 8 BMSH

CM_ BO_ 3221225472 "This is a message for not used signals, created by Vector CANdb++ DBC OLE DB Provider.";
CM_ SG_ 3221225472 DCDC_InCurOver "Input current too high alarm of DCDC";
CM_ SG_ 3221225472 DCDC_DataStorageFault "Data storage fault of DCDC";
CM_ SG_ 3221225472 DCDC_InternalComFault "Internal Communication fault of DCDC";
CM_ SG_ 3221225472 DCDC_BatVoltFault "Voltage Fault of Battery";
CM_ SG_ 3221225472 DCDC_OutInversed "Output Inversed alarm of DCDC";
CM_ SG_ 3221225472 IPU_IPUTempSensorFault "IPU temperature sensor fault";
CM_ SG_ 3221225472 IPU_5VUnderVoltageAlarm "5V Power under voltage alarm";
CM_ SG_ 3221225472 IPU_5VOverVoltageAlarm "5V Power over voltage alarm";
CM_ SG_ 3221225472 IPU_HVShortCircuit "High voltage short circuit fault";
CM_ SG_ 3221225472 IPU_IPUDrvModuleUV "IPU drive module under voltage";
CM_ SG_ 3221225472 IPU_MotModuleFault "Motor module fault";
CM_ BO_ 170 "VCU Control BMSH Message";
CM_ SG_ 170 VCU_BMSH_StsModeReq "VCU to BMSH control command";
CM_ SG_ 170 VCU_BMSH_Ctrl_AliveCounter "Signal counting the times of this message";
CM_ SG_ 170 VCU_StsCrash "Crash Signal detect by VCU";
CM_ SG_ 170 VCU_BMSH_Ctrl_CheckSum "Checksum of this message";
CM_ BO_ 171 "VCU Control IPU Message";
CM_ SG_ 171 VCU_IPU_StsModeReq "IPU Status Request ";
CM_ SG_ 171 VCU_IPU_CtrlModeReq "Control Mode Request";
CM_ SG_ 171 VCU_IPU_ActvDampgModReq "Mode signal for ISG damping.";
CM_ SG_ 171 VCU_IPU_TargetTqReq "Target torque Request ";
CM_ SG_ 171 VCU_IPU_TargetTqMax "Max Target torque";
CM_ SG_ 171 VCU_IPU_TargetTqMin "Min Target torque";
CM_ SG_ 171 VCU_IPU_Ctrl_AliveCounter "Signal counting the times of this message";
CM_ SG_ 171 VCU_IPU_Ctrl_CheckSum "Checksum of this message";
CM_ BO_ 563 "VCU Limit IPU Message";
CM_ SG_ 563 VCU_IPU_DischgPwrLim "Limit Motor Discharge Power";
CM_ SG_ 563 VCU_IPU_RegenPwrLim "Limit Motor Regen Power";
CM_ SG_ 563 VCU_IPU_Limit_AliveCounter "Signal counting the times of this message";
CM_ SG_ 563 VCU_IPU_Limit_CheckSum "Checksum of this message";
CM_ BO_ 564 "VCU Control Auxiliary System Message";
CM_ SG_ 564 VCU_DCDC_StsModeReq "VCU to DCDC control command";
CM_ SG_ 564 VCU_DCDC_VoltReq "VCU Request Volt";
CM_ SG_ 564 VCU_DCDC_CurrentLim "Limit DCDC Output Current";
CM_ SG_ 564 VCU_DCDC_PwrPermit "Permit DCDC Output Power";
CM_ SG_ 564 VCU_AuxSys_Ctrl_AliveCounter "Signal counting the times of this message";
CM_ SG_ 564 VCU_AuxSys_Ctrl_CheckSum "Checksum of this message";
CM_ BO_ 569 "VCU Fault Message";
CM_ SG_ 569 VCU_ChgFaultReq "VCU Request Charge Fault State";
CM_ SG_ 569 VCU_DischgFaultReq "VCU Request Discharge Fault State ";
CM_ BO_ 257 "Transmitted by PEPS";
CM_ BO_ 482 "Transmitted by PEPS , including PEPS singals
本消息由PEPS发出，包含PEPS的信息";
CM_ SG_ 482 PEPS_PowerModeValidity "PEPS Power Distribution StatusValidity bit
PEPS 电源模式有效指示位";
CM_ SG_ 482 PEPS_PowerMode "PEPS Power Distribution Status";
CM_ SG_ 645 BCM_DoorLockStatusDrv "Driver Door Lock Status";
CM_ SG_ 670 TBOX_Second "Second秒";
CM_ SG_ 670 TBOX_Minute "Minute分";
CM_ SG_ 670 TBOX_Hour "Hour小时";
CM_ SG_ 670 TBOX_Day "day天";
CM_ SG_ 670 TBOX_Month "Month月";
CM_ SG_ 670 TBOX_Year "Year年，基础年份为2000年";
CM_ BO_ 1009 "Transmitted by IPK , including Total Odometer";
CM_ SG_ 1009 IPK_IPKTotalOdometer "the total odometer displayed in IPK";
CM_ BO_ 185 "BMSH Status Message";
CM_ SG_ 185 BMSH_VCU_DischgFaultReq "BMSH Request VCU Discharge Fault State ";
CM_ SG_ 185 BMSH_StsDischgFault "BMSH's Discharge Fault State";
CM_ SG_ 185 BMSH_VCU_ChgFaultReq "BMSH Request VCU Charge Fault State";
CM_ SG_ 185 BMSH_StsChgFault "BMSH's Charge Fault State";
CM_ SG_ 185 BMSH_StsCellBalance "CellBalance Status";
CM_ SG_ 185 BMSH_StsPrecharge "Precharge Status";
CM_ SG_ 185 BMSH_StsMode "BMSH status Mode";
CM_ SG_ 185 BMSH_VCU_StsMainHVIL "Status of Bat HVIL";
CM_ SG_ 185 BMSH_StsInsulation "Insulation status";
CM_ SG_ 185 BMSH_StsCC2 "DC change CC2 State";
CM_ SG_ 185 BMSH_StsCC1 "DC charge CC1 State";
CM_ SG_ 185 BMSH_StsMainNegtiveRelay "Main negtive relay state of BMSH";
CM_ SG_ 185 BMSH_StsMainPositiveRelay "Main positive relay state of BMSH";
CM_ SG_ 185 BMSH_VCU_StsDCChgRelay "DC charge relay state of BMSH";
CM_ SG_ 185 BMSH_VCU_StsPreChgRelay "Precharge relay state of BMSH";
CM_ SG_ 185 BMSH_Status_AliveCounter "Signal counting the times of this message";
CM_ SG_ 185 BMSH_VCU_Crash " Crash (Hard wire) from ACU";
CM_ SG_ 185 BMSH_Status_CheckSum "Checksum of this message";
CM_ BO_ 532 "BMSH Ability Message(SOX)";
CM_ SG_ 532 BMSH_BatUseableSOC "Useable State of Charge";
CM_ SG_ 532 BMSH_BatRealSOC "Real State of Charge";
CM_ SG_ 532 BMSH_BatSOH "State of Health of the Battery";
CM_ SG_ 532 BMSH_BatSOE "State of Energy";
CM_ BO_ 533 "BMSH Power Message(SOP)";
CM_ SG_ 533 BMSH_VCU_BatChgAllowPwr "BMSH Allowed Charge Power";
CM_ SG_ 533 BMSH_VCU_BatDischgAllowPwr "BMSH Allowed Discharge Power";
CM_ SG_ 533 BMSH_VCU_BatChgContPwr "BMSH Cont Charge Power";
CM_ SG_ 533 BMSH_VCU_BatDischgContPwr "BMSH Cont Discharge Power";
CM_ SG_ 533 BMSH_VCU_BatChgPeakPwr "BMSH Peak  Charge Power";
CM_ SG_ 533 BMSH_VCU_BatDischgPeakPwr "BMSH Peak Discharge Power";
CM_ SG_ 533 BMSH_SOP_AliveCounter "Signal counting the times of this message";
CM_ SG_ 533 BMSH_SOP_CheckSum "Checksum of this message";
CM_ BO_ 186 "BMSH Voltage and Current and Power Message";
CM_ SG_ 186 BMSH_PackVolt "Actual Battery pack voltage";
CM_ SG_ 186 BMSH_BusVolt "Actual DC Bus voltage";
CM_ SG_ 186 BMSH_BatCurrent "Actual Battery current";
CM_ SG_ 186 BMSH_VoltCurrent_AliveCounter "Signal counting the times of this message";
CM_ SG_ 186 BMSH_VoltCurrent_CheckSum "Checksum of this message";
CM_ BO_ 534 "BMSH Cell Volt Current Message";
CM_ SG_ 534 BMSH_TBOX_CellVoltMaxID "Maximum voltage Cell Serial number ";
CM_ SG_ 534 BMSH_TBOX_CellVoltMinID "Minimum voltage Cell Serial number ";
CM_ SG_ 534 BMSH_CellVoltMaxModuleID "Maximum voltage Cell 's  Battery Subsystem Serial number ";
CM_ SG_ 534 BMSH_CellVoltMinModuleID "Minimum voltage Cell 's Battery Subsystem Serial number ";
CM_ SG_ 534 BMSH_CellVoltMax "Maximum voltage Cell";
CM_ SG_ 534 BMSH_CellVoltMin "Minimum voltage Cell";
CM_ BO_ 903 "BMSH  Temperature Message";
CM_ SG_ 903 BMSH_TBOX_MaxTempID "Maximum temperature Battery Serial number ";
CM_ SG_ 903 BMSH_TBOX_MinTempID "Minimum temperature Battery Serial number ";
CM_ SG_ 903 BMSH_VCU_DCChgPosTemp " The Positive Temperature of DC Charging Connector";
CM_ SG_ 903 BMSH_VCU_DCChgNegTemp " The Negative Temperature of DC Charging Connector";
CM_ SG_ 903 BMSH_BatTempMax "Maximum temperature of Battery";
CM_ SG_ 903 BMSH_BatTempMin "Minimum temperature of Battery";
CM_ SG_ 903 BMSH_BatTempAvg "Average temperature of Battery";
CM_ BO_ 535 "BMSH Cool Request Message";
CM_ SG_ 535 BMSH_CCM_LiquidInTemp "Liquid In Temperature ";
CM_ SG_ 535 BMSH_CCM_LiquidOutTemp "Liquid Out Temperature ";
CM_ SG_ 535 BMSH_CCM_InletTargetTemp "Inlet target temperature";
CM_ SG_ 535 BMSH_CCM_ThermalManageReq "ThermalManageRequire";
CM_ SG_ 535 BMSH_CCM_Req_AliveCounter "Signal counting the times of this message";
CM_ SG_ 535 BMSH_CCM_Req_CheckSum "Checksum of this message";
CM_ BO_ 537 "BMSH OBC Control Message";
CM_ SG_ 537 BMSH_OBC_StsModeReq "BMSH Mode Request of OBC";
CM_ SG_ 537 BMSH_OBC_MaxVoltReq "BMSH Max Voltage Request ";
CM_ SG_ 537 BMSH_OBC_MaxCurReq "BMSH Max Current Request ";
CM_ SG_ 537 BMSH_OBC_Ctrl_AliveCounter "Signal counting the times of this message";
CM_ SG_ 537 BMSH_OBC_Ctrl_CheckSum "Checksum of this message";
CM_ BO_ 543 "BMSH Charge Information Message";
CM_ SG_ 543 BMSH_DCChargeProcess "DC Charge Process";
CM_ SG_ 543 BMSH_DCChgEnder "DC Charge Ender";
CM_ SG_ 543 BMSH_DCChgStandVer "Version Number of DC Charge";
CM_ SG_ 543 BMSH_DCChgVoltAllow "BMSH Allow DC Charge Voltage";
CM_ SG_ 543 BMSH_DCEquipment_DisplayVolt "DC equipment display Voltage";
CM_ SG_ 543 BMSH_FinishChgTime "Time to fully charged (minute)";
CM_ SG_ 543 BMSH_DCChgCurReq "BMSH Request DC Charge Current";
CM_ SG_ 543 BMSH_DCEquipment_DisplayCur "DC equipment display current";
CM_ BO_ 904 "BMSH Fault Message";
CM_ SG_ 904 BMSH_ChgOverCurrent "Charge over current alarm";
CM_ SG_ 904 BMSH_DisChgOverCurrent "Discharge over current alarm";
CM_ SG_ 904 BMSH_CellOverVolt "Cell voltage too high alarm";
CM_ SG_ 904 BMSH_CellUnderVolt "Cell voltage too low alarm";
CM_ SG_ 904 BMSH_ChgOverTemp "Battery Charge Temperature too high alarm";
CM_ SG_ 904 BMSH_BatUnderVolt "Battery voltage too low alarm";
CM_ SG_ 904 BMSH_BatOverVolt "Battery voltage too high alarm";
CM_ SG_ 904 BMSH_CellDiffVoltUniform "The difference of cell voltage is too large alarm";
CM_ SG_ 904 BMSH_CellTempUniformity "Battery CellTempUniformity";
CM_ SG_ 904 BMSH_DisChgUnderTemp "Battery DisCharge Temperature too low alarm";
CM_ SG_ 904 BMSH_DisChgOverTemp "Battery DisCharge Temperature too high alarm";
CM_ SG_ 904 BMSH_ChgUnderTemp "Battery Charge Temperature too low alarm";
CM_ SG_ 904 BMSH_MainPosRelayFault "MainRelay Pos Fault";
CM_ SG_ 904 BMSH_RecoveryOverCurrent "Recovery Current too large alarm";
CM_ SG_ 904 BMSH_BatUnderSOC "Battery SOC too low alarm";
CM_ SG_ 904 BMSH_BatOverSOC "Battery SOC too high alarm";
CM_ SG_ 904 BMSH_DCChgPlugNOverTemp "FastChargingPlugNEG_Temperature_TooHigh";
CM_ SG_ 904 BMSH_DCChgPlugPOverTemp "FastChargingPlugPOS_Temperature_TooHigh";
CM_ SG_ 904 BMSH_DCChgRelayFault "DC ChargeRelay Fault";
CM_ SG_ 904 BMSH_MainNegRelayFault "MainRelay Neg Fault";
CM_ SG_ 904 BMSH_IntComFault "CAN Intcommunication fault";
CM_ SG_ 904 BMSH_DisChgComFault "CAN Discommunication fault";
CM_ SG_ 904 BMSH_FastChgComFault "CAN Fastcommunication fault";
CM_ SG_ 904 BMSH_12VBatFault "12V_Battery fault";
CM_ SG_ 904 BMSH_ConnectPosOverTemp "Connect Positive Temperature TooHigh";
CM_ SG_ 904 BMSH_ConnectNegOverTemp "Connect Negetive Temperature  TooHigh";
CM_ SG_ 904 BMSH_VCUChksumFault "VCU CheckSum fault";
CM_ SG_ 904 BMSH_VCURollCountFault "VCU RollingCounter fault";
CM_ SG_ 904 BMSH_OBCChksumFault "OBC CheckSum fault";
CM_ SG_ 904 BMSH_OBCRollCountFault "OBC RollingCounter fault";
CM_ SG_ 904 BMSH_SelfCheckFault "Self check fault";
CM_ SG_ 904 BMSH_DataStorageFault "Data storage fault";
CM_ SG_ 904 BMSH_FaultCode "BMSH Fault Code";
CM_ BO_ 909 "BMSH  to TBOX information Message1";
CM_ SG_ 909 BMSH_TBOX_BatProductYear "Battery Productive Year";
CM_ SG_ 909 BMSH_TBOX_BatProductMonth "Battery Productive Month";
CM_ SG_ 909 BMSH_TBOX_BatRatedCap "Battery pack rated capacity";
CM_ SG_ 909 BMSH_TBOX_BatProductDay "Battery Productive Day";
CM_ SG_ 909 BMSH_TBOX_BatRatedVolt "Battery pack rated voltage";
CM_ SG_ 909 BMSH_TBOX_CellRatedVolt "Cell rated voltage";
CM_ BO_ 910 "BMSH  to TBOX information Message2";
CM_ SG_ 910 BMSH_TBOX_BatTempSum "Battery pack temperature test quantity";
CM_ SG_ 910 BMSH_TBOX_BatSeriesCellsSum "Series Cell quantity  in Battery";
CM_ SG_ 910 BMSH_TBOX_BatModuleSum "Total number of  Battery Module";
CM_ SG_ 910 BMSH_TBOX_CellsSum "Cell quantity";
CM_ BO_ 911 "BMSH  to TBOX information Message3";
CM_ SG_ 911 BMSH_TBOX_HWVer "Hardware Version";
CM_ SG_ 911 BMSH_TBOX_SWVer "Software Version";
CM_ SG_ 911 BMSH_TBOX_BatType "Battery material";
CM_ SG_ 911 BMSH_TBOX_BatSysSerialNum "Battery System Serial Number";
CM_ BO_ 538 "Cell Voltage Message";
CM_ SG_ 538 BMSH_TBOX_CellA_ID "Cell A ID";
CM_ SG_ 538 BMSH_TBOX_CellC_ID "Cell C ID";
CM_ SG_ 538 BMSH_TBOX_CellA_Volt "Cell A Voltage";
CM_ SG_ 538 BMSH_TBOX_CellB_Volt "Cell B Voltage";
CM_ SG_ 538 BMSH_TBOX_CellC_Volt "Cell C Voltage";
CM_ BO_ 539 "Cell Tempreture Message";
CM_ SG_ 539 BMSH_TBOX_TempA_ID "Temp A ID";
CM_ SG_ 539 BMSH_TBOX_TempF_ID "Temp F ID";
CM_ SG_ 539 BMSH_TBOX_TempA "ID A Temp";
CM_ SG_ 539 BMSH_TBOX_TempB "ID B Temp";
CM_ SG_ 539 BMSH_TBOX_TempC "ID C Temp";
CM_ SG_ 539 BMSH_TBOX_TempD "ID D Temp";
CM_ SG_ 539 BMSH_TBOX_TempE "ID E Temp";
CM_ SG_ 539 BMSH_TBOX_TempF "ID F Temp";
CM_ BO_ 905 "BMSH Fault to TBOX  Message";
CM_ SG_ 905 BMSH_TBOX_BatFaultList "The list of Battery Fault";
CM_ SG_ 905 BMSH_TBOX_BatOverTemp "Battery Over Temperature alarm";
CM_ SG_ 905 BMSH_TBOX_BatLowTemp "Battery Under Temperature alarm";
CM_ SG_ 905 BMSH_TBOX_BatOverVoltage "Battery pack Under Voltage alarm";
CM_ SG_ 905 BMSH_TBOX_BatUnderVoltage "Battery pack Over Voltage alarm";
CM_ SG_ 905 BMSH_TBOX_BatStoreSysFault "Battery StoredEnergySystem Fault";
CM_ SG_ 905 BMSH_TBOX_BatIsoAlarm "Battery insulation alarm";
CM_ SG_ 905 BMSH_TBOX_BatHVILFault "Battery HVILFault";
CM_ SG_ 905 BMSH_TBOX_BatMismatching "Battery mismatching";
CM_ SG_ 905 BMSH_TBOX_CellOverVoltage "Cell Over Voltage alarm";
CM_ SG_ 905 BMSH_TBOX_CellUnderVoltage "Cell Under Voltage alarm";
CM_ SG_ 905 BMSH_TBOX_BatUniformity "Battery Uniformity";
CM_ SG_ 905 BMSH_TBOX_BatOverCharge "Battery Over charge alarm";
CM_ SG_ 905 BMSH_TBOX_SOCHop "Battery SOC Hop alarm";
CM_ SG_ 905 BMSH_TBOX_BatOverSOC "Battery Over SOC alarm";
CM_ SG_ 905 BMSH_TBOX_BatLowSOC "Battery Under SOC alarm";
CM_ SG_ 905 BMSH_TBOX_BatTempUniformity "Battery Temp Uniformity";
CM_ SG_ 905 BMSH_DCChgRx_OTime_CSD "DC Charge CSD Recevie Over Time";
CM_ SG_ 905 BMSH_DCChgRx_OTime_CCS "DC Charge CCS Recevie Over Time";
CM_ SG_ 905 BMSH_DCChgRx_OTime_CROAA "DC Charge CRO0AA Recevie Over Time";
CM_ SG_ 905 BMSH_DCChgRx_OTime_CRO00 "DC Charge CRO00 Recevie Over Time";
CM_ SG_ 905 BMSH_DCChgRx_OTime_CML "DC Charge CML Recevie Over Time";
CM_ SG_ 905 BMSH_DCChgRx_OTime_CRMAA "DC Charge CRMAA Recevie Over Time";
CM_ SG_ 905 BMSH_DCChgRx_OTime_CRM00 "DC Charge CRM00 Recevie Over Time";
CM_ SG_ 905 BMSH_TBOX_InsulationResistance "Insulation Resistance";
CM_ BO_ 662 "DCDC Status  Message";
CM_ SG_ 662 DCDC_VCU_OutputCurrent "Output Current";
CM_ SG_ 662 DCDC_StsCtrl "DCDC Control Status to VCU";
CM_ SG_ 662 DCDC_StsDCDCFault "DCDC Fault Status";
CM_ SG_ 662 DCDC_VCU_InputCurrent "Input Current";
CM_ SG_ 662 DCDC_VCU_OutputVolt "Output Voltage";
CM_ SG_ 662 DCDC_VCU_InputVolt "Input Voltage";
CM_ SG_ 662 HVAS_BMSH_DCChgRelayVolt "DC Charge Relay Volt";
CM_ SG_ 662 DCDC_Status_CheckSum "Checksum of this message";
CM_ BO_ 663 "DCDC Temp and Fault  Message";
CM_ SG_ 663 DCDC_VCU_Temp "Temperature";
CM_ SG_ 663 DCDC_VCU_OverTemp "Temperature too high alarm of DCDC";
CM_ SG_ 663 DCDC_HWFault "Hardware Fault of DCDC";
CM_ SG_ 663 DCDC_OutPwrOver "Output power over alarm of DCDC";
CM_ SG_ 663 DCDC_OutCurOver "Output current too high alarm of DCDC";
CM_ SG_ 663 DCDC_OutVoltOver "Output voltage too high alarm of DCDC";
CM_ SG_ 663 DCDC_OutVoltUnder "Output voltage too low alarm of DCDC";
CM_ SG_ 663 DCDC_InVoltOver "Input voltage too high alarm of DCDC";
CM_ SG_ 663 DCDC_InVoltUnder "Input voltage too low alarm of DCDC";
CM_ SG_ 663 DCDC_OutCircuitShort "Output Short circuit alarm of DCDC";
CM_ SG_ 663 DCDC_VCULostFault "Communication TimeOut Fault";
CM_ SG_ 663 DCDC_CANBusoffFault "Communication Missing Fault";
CM_ SG_ 663 DCDC_WakeupInMissing "WakeupInput Missing Fault";
CM_ SG_ 663 DCDC_12VFault "12V supply Fault";
CM_ BO_ 201 "IPU Status  Message";
CM_ SG_ 201 IPU_VCU_IPUFaultReq "IPU  Fault Status Request";
CM_ SG_ 201 IPU_StsIPUFault "IPU Fault Status";
CM_ SG_ 201 IPU_VCU_CtrlMode "IPU control mode";
CM_ SG_ 201 IPU_VCU_StsMode "Operating Mode";
CM_ SG_ 201 IPU_MotorTq "Motor torque";
CM_ SG_ 201 IPU_MotorSpd "Motor rotating speed";
CM_ SG_ 201 IPU_Status_AliveCounter "Signal counting the times of this message";
CM_ SG_ 201 IPU_ReleaseSig "VCU receives Release signal from IPU";
CM_ SG_ 201 IPU_MotorSpdInvalid "Motor rotating speed Invalid";
CM_ SG_ 201 IPU_MotorTqInvalid "Motor torque Invalid";
CM_ SG_ 201 IPU_Status_CheckSum "Checksum of this message";
CM_ BO_ 202 "IPU Ability Message";
CM_ SG_ 202 IPU_VCU_PosTrqLmt "Maximum positive Torque available (motor) for Torque requests";
CM_ SG_ 202 IPU_VCU_NegTrqLmt "Maximum negative torque available (generator) for Torque requests";
CM_ SG_ 202 IPU_ActInputVolt "Motor Actual input DC voltage";
CM_ SG_ 202 IPU_ActInputCurrent "Motor Actual input DC current";
CM_ SG_ 202 IPU_Ability_AliveCounter "Signal counting the times of this message";
CM_ SG_ 202 IPU_Ability_CheckSum "Checksum of this message";
CM_ BO_ 871 "IPU temperature Message";
CM_ SG_ 871 IPU_IPUTemp "IPU internal temperature";
CM_ SG_ 871 IPU_MotorTemp "Motor temperature";
CM_ SG_ 871 IPU_Temp_AliveCounter "Signal counting the times of this message";
CM_ SG_ 871 IPU_Temp_CheckSum "Checksum of this message";
CM_ BO_ 872 "IPU Fault Message";
CM_ SG_ 872 IPU_IPUOverTempFault "IPU over temperture fault";
CM_ SG_ 872 IPU_IPUOverTempAlarm "IPU over temperture alarm";
CM_ SG_ 872 IPU_MotTempSenUFault "Motor temperature sensorV fault";
CM_ SG_ 872 IPU_MotTempSenFault "Motor temperature sensorU fault";
CM_ SG_ 872 IPU_MotOverTempFault "Motor over temperture fault";
CM_ SG_ 872 IPU_MotOverTempAlarm "Motor over temperture alarm";
CM_ SG_ 872 IPU_HVUnderVoltage2 "IPU high voltage ultra voltage fault level2";
CM_ SG_ 872 IPU_HVUnderVoltage1 "IPU high voltage ultra voltage fault level1";
CM_ SG_ 872 IPU_HVOverVoltage2 "IPU high voltage over voltage fault level2";
CM_ SG_ 872 IPU_HVOverVoltage1 "IPU high voltage over voltage fault level1";
CM_ SG_ 872 IPU_IPUCPhsSenRatFault "IPU C phase current sensor fault";
CM_ SG_ 872 IPU_IPUAPhsSenRatFault "IPU A phase current sensor fault";
CM_ SG_ 872 IPU_PhaseOverCurrentHWFault "Motor over current fault";
CM_ SG_ 872 IPU_MotOverSpd2 "Motor overspeed fault level2";
CM_ SG_ 872 IPU_MotOverSpd1 "Motor overspeed fault level1";
CM_ SG_ 872 IPU_12VUnderVoltageAlarm "12V Power under voltage alarm";
CM_ SG_ 872 IPU_12VOverVoltageAlarm "12V Power over voltage alarm";
CM_ SG_ 872 IPU_IPUHVSensorFault "IPU high voltage sensor fault";
CM_ SG_ 872 IPU_IPUDisChgFault "IPU discharge fault";
CM_ SG_ 872 IPU_IPUEnableFault "IPU enable fault";
CM_ SG_ 872 IPU_MotTrqChksumFault "Motor torque Checksum fault";
CM_ SG_ 872 IPU_MotTrqLimFault "Motor torque limit fault";
CM_ SG_ 872 IPU_MotTrqFault "Motor torque fault";
CM_ SG_ 872 IPU_IPUBlockedFault "IPU blocked fault";
CM_ SG_ 872 IPU_MotRotSenFault "Motor resolver fault";
CM_ SG_ 872 IPU_BMSHLostFault "BMSH lost communication fault";
CM_ SG_ 872 IPU_VCULostFault "VCU lost communication fault";
CM_ SG_ 872 IPU_CANBusoffFault "CAN busoff fault";
CM_ SG_ 872 IPU_IGBTDrvPwrFault "IGBT drive power fault";
CM_ SG_ 872 IPU_IPUFaultCode "IPU Fault Code";
CM_ BO_ 256 "IPU Authentication Code Message";
CM_ SG_ 256 IPU_BCM_Auth "Anti-theft Authentication Code";
CM_ BO_ 873 "IPU Information";
CM_ SG_ 873 IPU_TBOX_FaultAmount "System fault amount";
CM_ SG_ 873 IPU_TBOX_FaultList "System Fault List";
CM_ SG_ 873 IPU_StsActiveDischg "IPU Active discharge state";
CM_ SG_ 873 IPU_TBOX_ModeMotorDrv "Motor driving mode";
CM_ SG_ 873 IPU_MotorTempU "Motor U temperature";
CM_ SG_ 873 IPU_MotorTempV "Motor V temperature";
CM_ BO_ 694 "OBC Status Message";
CM_ SG_ 694 OBC_StsMode "Mode Status";
CM_ SG_ 694 OBC_BMSH_ChgFaultReq "System Charge Fault Status Request";
CM_ SG_ 694 OBC_StsCP "CP State";
CM_ SG_ 694 OBC_StsChgCC "Charge CC State";
CM_ SG_ 694 OBC_BMSH_PWMCP "OBC to BMSH CP PWM Singal";
CM_ SG_ 694 OBC_StsElock "OBC Electronic Lock status";
CM_ SG_ 694 OBC_Status_AliveCounter "Signal counting the times of this message";
CM_ SG_ 694 OBC_Status_CheckSum "Checksum of this message";
CM_ BO_ 695 "OBC Ability Message";
CM_ SG_ 695 OBC_BMSH_MaxCurDC "DC Max Output Current Available";
CM_ SG_ 695 OBC_BMSH_MaxCurAC "AC Max Input Current Available";
CM_ SG_ 695 OBC_BMSH_ActVoltDC "DC actual Voltage";
CM_ SG_ 695 OBC_BMSH_ActCurDC "DC actual current";
CM_ SG_ 695 OBC_BMSH_ActVoltAC "AC actual Voltage";
CM_ SG_ 695 OBC_BMSH_ActCurAC "AC actual current";
CM_ BO_ 919 "OBC Temperature Message";
CM_ SG_ 919 OBC_OBCTemp "Temperature1 of OBC";
CM_ SG_ 919 OBC_InletTemp "Temperature of OBC Cooling Inlet";
CM_ SG_ 919 OBC_ACInletLTerminalTemp "Temperature of AC Inlet L terminal ";
CM_ SG_ 919 OBC_ACInletNTerminalTemp "Temperature of AC Inlet N terminal ";
CM_ SG_ 919 OBC_BMSH_NTerminalOverTemp "N_Terminal Temperature too low alarm of OBC ";
CM_ SG_ 919 OBC_BMSH_LTerminalOverTemp "L_Terminal Temperature too low alarm of OBC ";
CM_ SG_ 919 OBC_InletTempSenFault "OBC Inlet Temperature Sensar Fault";
CM_ BO_ 920 "OBC Fault Message";
CM_ SG_ 920 OBC_InputACinterrupt "AC input  interrupt alarm of OBC";
CM_ SG_ 920 OBC_InputOverCurrent "Input current too high alarm of OBC";
CM_ SG_ 920 OBC_InputOverVoltage "Input voltage too high alarm of OBC";
CM_ SG_ 920 OBC_InputUnderVoltage "Input voltage too low alarm of OBC";
CM_ SG_ 920 OBC_12VFault "12V supply Fault";
CM_ SG_ 920 OBC_S2ControlFault "S2ControlFault";
CM_ SG_ 920 OBC_OverTemp "Temperature too low alarm of OBC ";
CM_ SG_ 920 OBC_ComTimeOut "Communication TimeOut Fault";
CM_ SG_ 920 OBC_WakeUpInputMiss "WakeupInput Missing Fault";
CM_ SG_ 920 OBC_BatteryVoltageFault "Voltage Fault of Battery";
CM_ SG_ 920 OBC_OutputInversed "Output Inversed alarm of OBC";
CM_ SG_ 920 OBC_OutputShortCircuit "Output Short circuit alarm of OBC";
CM_ SG_ 920 OBC_OutputOverCurrent "Output current too high alarm of OBC";
CM_ SG_ 920 OBC_OutputOverVoltage "Output voltage too high alarm of OBC";
CM_ SG_ 920 OBC_OutputUnderVoltage "Output voltage too low alarm of OBC";
CM_ SG_ 920 OBC_InternalComFault "Internal Communication fault of OBC";
CM_ SG_ 920 OBC_DataStorageFault "Data storage fault of OBC";
CM_ SG_ 920 OBC_HWFault "Hardware Fault of OBC";
CM_ SG_ 920 OBC_ComMissing "Communication Missing Fault";
CM_ BO_ 2015 "Transmitted by TESTER";
CM_ BO_ 2022 "Transmitted by TESTER";
CM_ BO_ 2030 "Transmitted by VCU";
CM_ BO_ 2019 "Transmitted by TESTER";
CM_ BO_ 2027 "Transmitted by IPU";
CM_ BO_ 1972 "Transmitted by TESTER";
CM_ BO_ 1980 "Transmitted by DCDC";
CM_ BO_ 2023 "Transmitted by TESTER";
CM_ BO_ 2031 "Transmitted by OBC";
CM_ BO_ 2018 "Transmitted by TESTER";
CM_ BO_ 2026 "Transmitted by BMSH";
BA_DEF_ BO_  "GenMsgSendType" ENUM  "Cycle","NoSendType","IfActive";
BA_DEF_ BO_  "GenMsgCycleTime" INT 0 0;
BA_DEF_ SG_  "GenSigSendType" ENUM  "Cycle","OnChange","OnWrite","IfActive","OnChangeWithRepetition","OnWriteWithRepetition","IfActiveWithRepetition";
BA_DEF_ SG_  "GenSigStartValue" INT 0 0;
BA_DEF_  "DBName" STRING ;
BA_DEF_ BU_  "NodeLayerModules" STRING ;
BA_DEF_ BU_  "ILUsed" ENUM  "No","Yes";
BA_DEF_ BU_  "NmNode" ENUM  "Not","Yes";
BA_DEF_  "NmBaseAddress" HEX 0 2047;
BA_DEF_  "NmMessageCount" INT 0 255;
BA_DEF_ BO_  "GenMsgILSupport" ENUM  "No","Yes";
BA_DEF_  "BusType" STRING ;
BA_DEF_DEF_  "GenMsgSendType" "Cycle";
BA_DEF_DEF_  "GenMsgCycleTime" 0;
BA_DEF_DEF_  "GenSigSendType" "Cycle";
BA_DEF_DEF_  "GenSigStartValue" 0;
BA_DEF_DEF_  "DBName" "";
BA_DEF_DEF_  "NodeLayerModules" "CANoeILNLVector.dll";
BA_DEF_DEF_  "ILUsed" "Yes";
BA_DEF_DEF_  "NmNode" "Not";
BA_DEF_DEF_  "NmBaseAddress" 1024;
BA_DEF_DEF_  "NmMessageCount" 128;
BA_DEF_DEF_  "GenMsgILSupport" "Yes";
BA_DEF_DEF_  "BusType" "CAN";
BA_ "DBName" "PCAN";
BA_ "GenMsgCycleTime" BO_ 354 20;
BA_ "GenMsgCycleTime" BO_ 170 10;
BA_ "GenMsgCycleTime" BO_ 171 10;
BA_ "GenMsgCycleTime" BO_ 563 100;
BA_ "GenMsgCycleTime" BO_ 564 100;
BA_ "GenMsgCycleTime" BO_ 569 500;
BA_ "GenMsgSendType" BO_ 257 1;
BA_ "GenMsgCycleTime" BO_ 482 20;
BA_ "GenMsgCycleTime" BO_ 645 100;
BA_ "GenMsgCycleTime" BO_ 670 1000;
BA_ "GenMsgCycleTime" BO_ 1009 1000;
BA_ "GenMsgCycleTime" BO_ 185 10;
BA_ "GenMsgCycleTime" BO_ 532 100;
BA_ "GenMsgCycleTime" BO_ 533 100;
BA_ "GenMsgCycleTime" BO_ 186 10;
BA_ "GenMsgCycleTime" BO_ 534 100;
BA_ "GenMsgCycleTime" BO_ 903 500;
BA_ "GenMsgCycleTime" BO_ 535 100;
BA_ "GenMsgCycleTime" BO_ 537 100;
BA_ "GenMsgCycleTime" BO_ 543 200;
BA_ "GenMsgCycleTime" BO_ 904 500;
BA_ "GenMsgCycleTime" BO_ 909 1000;
BA_ "GenMsgCycleTime" BO_ 910 1000;
BA_ "GenMsgCycleTime" BO_ 911 1000;
BA_ "GenMsgCycleTime" BO_ 538 100;
BA_ "GenMsgCycleTime" BO_ 539 100;
BA_ "GenMsgCycleTime" BO_ 905 500;
BA_ "GenMsgCycleTime" BO_ 662 100;
BA_ "GenMsgCycleTime" BO_ 663 100;
BA_ "GenMsgCycleTime" BO_ 201 10;
BA_ "GenMsgCycleTime" BO_ 202 10;
BA_ "GenMsgCycleTime" BO_ 871 500;
BA_ "GenMsgCycleTime" BO_ 872 500;
BA_ "GenMsgSendType" BO_ 256 1;
BA_ "GenMsgCycleTime" BO_ 873 500;
BA_ "GenMsgCycleTime" BO_ 694 100;
BA_ "GenMsgCycleTime" BO_ 695 100;
BA_ "GenMsgCycleTime" BO_ 919 500;
BA_ "GenMsgCycleTime" BO_ 920 500;
BA_ "GenMsgSendType" BO_ 2015 1;
BA_ "GenMsgSendType" BO_ 2022 1;
BA_ "GenMsgSendType" BO_ 2030 1;
BA_ "GenMsgSendType" BO_ 2019 1;
BA_ "GenMsgSendType" BO_ 2027 1;
BA_ "GenMsgSendType" BO_ 1972 1;
BA_ "GenMsgSendType" BO_ 1980 1;
BA_ "GenMsgSendType" BO_ 2023 1;
BA_ "GenMsgSendType" BO_ 2031 1;
BA_ "GenMsgSendType" BO_ 2018 1;
BA_ "GenMsgSendType" BO_ 2026 1;
BA_ "GenSigSendType" SG_ 257 PEPS_IMMOCode 2;
BA_ "GenSigStartValue" SG_ 645 BCM_DoorLockStatusDrv 2;
BA_ "GenSigStartValue" SG_ 670 TBOX_Day 1;
BA_ "GenSigStartValue" SG_ 670 TBOX_Month 1;
BA_ "GenSigStartValue" SG_ 532 BMSH_BatUseableSOC 50;
BA_ "GenSigStartValue" SG_ 532 BMSH_BatRealSOC 50;
BA_ "GenSigStartValue" SG_ 532 BMSH_BatSOH 100;
BA_ "GenSigStartValue" SG_ 903 BMSH_BatTempMax 25;
BA_ "GenSigStartValue" SG_ 903 BMSH_BatTempMin 25;
BA_ "GenSigStartValue" SG_ 903 BMSH_BatTempAvg 25;
BA_ "GenSigStartValue" SG_ 909 BMSH_TBOX_BatProductMonth 1;
BA_ "GenSigStartValue" SG_ 909 BMSH_TBOX_BatProductDay 1;
BA_ "GenSigStartValue" SG_ 539 BMSH_TBOX_TempA 25;
BA_ "GenSigStartValue" SG_ 539 BMSH_TBOX_TempB 25;
BA_ "GenSigStartValue" SG_ 539 BMSH_TBOX_TempC 25;
BA_ "GenSigStartValue" SG_ 539 BMSH_TBOX_TempD 25;
BA_ "GenSigStartValue" SG_ 539 BMSH_TBOX_TempE 25;
BA_ "GenSigStartValue" SG_ 539 BMSH_TBOX_TempF 25;
BA_ "GenSigSendType" SG_ 256 IPU_BCM_Auth 2;
VAL_ 3221225472 DCDC_InCurOver 0 "Normal(正常)" 1 "Error(异常)" ;
VAL_ 3221225472 DCDC_DataStorageFault 0 "Normal(正常)" 1 "Error(异常)" ;
VAL_ 3221225472 DCDC_InternalComFault 0 "Normal(正常)" 1 "Error(异常)" ;
VAL_ 3221225472 DCDC_BatVoltFault 0 "Normal(正常)" 1 "Error(异常)" ;
VAL_ 3221225472 DCDC_OutInversed 0 "Normal(正常)" 1 "Error(异常)" ;
VAL_ 3221225472 IPU_IPUTempSensorFault 0 "Normal(正常)" 1 "Error(异常)" ;
VAL_ 3221225472 IPU_5VUnderVoltageAlarm 0 "Normal(正常)" 1 "Error(异常)" ;
VAL_ 3221225472 IPU_5VOverVoltageAlarm 0 "Normal(正常)" 1 "Error(异常)" ;
VAL_ 3221225472 IPU_HVShortCircuit 0 "Normal(正常)" 1 "Error(异常)" ;
VAL_ 3221225472 IPU_IPUDrvModuleUV 0 "Normal(正常)" 1 "Error(异常)" ;
VAL_ 3221225472 IPU_MotModuleFault 0 "Normal(正常)" 1 "Error(异常)" ;
VAL_ 293 ABS_VehicleSpeedInvalid 1 "invalid" 0 "valid" ;
VAL_ 354 VCU_ePTReady 1 "PTReady  Active" 0 "PTReady Not Active" ;
VAL_ 170 VCU_BMSH_StsModeReq 2 "Standby(待机)" 4 "Normal(正常运行)" 10 "ChargeAllowed(允许充电)" 11 "ShutDown(关闭)" ;
VAL_ 170 VCU_StsCrash 0 "Default(默认值)" 1 "No crashed(未碰撞)" 2 "Crashed(碰撞)" 3 "Reserved(预留)" ;
VAL_ 171 VCU_IPU_StsModeReq 0 "Default(默认值)" 1 "Init(初始化)" 3 "Precharge (预充)" 2 "Standby(待机)" 4 "Normal(正常运行)" 7 "EmDischarge(紧急放电)(预留)" 11 "ShutDown(关闭)" 15 "Invalid(无效)" ;
VAL_ 171 VCU_IPU_CtrlModeReq 0 "Inactive(非激活)" 1 "TqCtrl(扭矩控制)" 2 "Anti-slideSlope(防溜坡)" 3 "Reserved(预留)" ;
VAL_ 171 VCU_IPU_ActvDampgModReq 0 "No damping" 1 "Low damping" 2 "Medium damping" 3 "High damping" ;
VAL_ 564 VCU_DCDC_StsModeReq 0 "Inactive(不工作)" 1 "Buck(降压)" 2 "Active Discharge(主动放电)(预留)" 3 "Reserved(预留)" ;
VAL_ 569 VCU_ChgFaultReq 0 "Normal(正常)" 6 "Powerdown(下高压)" 15 "Invalid(无效)" ;
VAL_ 569 VCU_DischgFaultReq 0 "Init(初始化)(预留)" 1 "Normal(正常)" 3 "Warning(报警)" 5 "Derating(降功率)" 7 "Limphome(跛行回家)" 9 "ZeroTorque(零扭矩)" 11 "Powerdown(延迟下电)" 13 "EmPowerdown(紧急下电)" 15 "Invalid(无效)" ;
VAL_ 482 PEPS_PowerModeValidity 0 "Not available" 1 "Invalid" 2 "Valid" 3 "Reserved" ;
VAL_ 482 PEPS_PowerMode 0 "OFF" 1 "ACC" 2 "ON" 3 "START-Reserved" 4 "START" 5 "START-Reserved" ;
VAL_ 645 BCM_DoorLockStatusDrv 0 "Unlocked" 1 "Locked" 2 "Reserved" 3 "Error (Reserved)" ;
VAL_ 1009 IPK_IPKTotalOdometer 16777214 "Abnormal" 16777215 "Invalid" ;
VAL_ 185 BMSH_VCU_DischgFaultReq 9 "ZeroTorque(零扭矩)" 7 "Limphome(跛行回家)" 0 "Init(初始化)" 1 "Normal(正常)" 5 "Derating(降功率)" 11 "Powerdown(延迟下电)" 13 "emPowerdown(紧急下电)" 15 "Invalid(无效)" ;
VAL_ 185 BMSH_StsDischgFault 0 "Normal(正常)" 1 "Fault Level I(1级故障)" 2 "Fault Level II(2级故障)" 3 "Fault Level III(3级故障)" 4 "Fault Level III(4级故障)" 5 "Fault Level III(5级故障)" ;
VAL_ 185 BMSH_VCU_ChgFaultReq 0 "Normal(正常)" 2 "Derating(降功率)" 3 "Recover ProhibitCharge(可恢复的禁止充电)" 6 "Powerdown(下高压)" 15 "Invalid(无效)" ;
VAL_ 185 BMSH_StsChgFault 0 "Normal(正常)" 1 "Fault Level I(1级故障)" 2 "Fault Level II(2级故障)" 3 "Fault Level III(3级故障)" 4 "Fault Level III(4级故障)" 5 "Fault Level III(5级故障)" ;
VAL_ 185 BMSH_StsCellBalance 0 "Default(默认)" 1 "Balancing(均衡中)" 2 "Balance finished(均衡完成)" 3 "Balance failed(均衡失败)" ;
VAL_ 185 BMSH_StsPrecharge 0 "Default(默认)" 1 "Precharging(预充中)" 2 "Precharge finished(预充完成)" 3 "Precharge failed(预充失败)" ;
VAL_ 185 BMSH_StsMode 0 "Default(默认值)(保留)" 1 "Init(初始化)" 2 "Standby(待机)" 3 "Precharge (预充)" 4 "Normal(正常运行)" 5 "Slow Charge(慢充)" 6 "Station Charge(站内充电)" 8 "Fast Charge(快充)" 9 "Heating/Cooling(预热/冷)" 11 "ShutDown(关闭)" 12 "AfterRun(运行后)" 13 "End of charge(充电完成)" 14 "PowerOff(下电)(保留)" 15 "Invalid(无效)" ;
VAL_ 185 BMSH_VCU_StsMainHVIL 0 "Normal(正常)" 1 "Error(异常)" 2 "Reserved(预留)" 3 "Invalid(无效)" ;
VAL_ 185 BMSH_StsInsulation 0 "Normal(正常)" 1 "Fault Level I(1级故障)" 2 "Fault Level II(2级故障)" 3 "Reserved(预留)" ;
VAL_ 185 BMSH_StsCC2 0 "Disconnect(未连接)" 1 "Connect Vehicle(车辆连接)" 2 "Reserved(保留)" 3 "Connect Abnormal(连接异常)" ;
VAL_ 185 BMSH_StsCC1 0 "Disconnect(未连接)" 1 "Connect(连接)" 2 "Reserved(预留)" 3 "Reserved(预留)" ;
VAL_ 185 BMSH_StsMainNegtiveRelay 0 "Init(初期化)" 1 "Open(断开)" 2 "Closed(关闭)" 3 "Adhesion(粘连)" ;
VAL_ 185 BMSH_StsMainPositiveRelay 0 "Init(初期化)" 1 "Open(断开)" 2 "Closed(关闭)" 3 "Adhesion(粘连)" ;
VAL_ 185 BMSH_VCU_StsDCChgRelay 0 "Init(初期化)" 1 "Open(断开)" 2 "Closed(关闭)" 3 "Adhesion(粘连)" ;
VAL_ 185 BMSH_VCU_StsPreChgRelay 0 "Init(初期化)" 1 "Open(断开)" 2 "Closed(关闭)" 3 "Adhesion(粘连)" ;
VAL_ 185 BMSH_VCU_Crash 0 "Normal(正常)" 1 "Error(异常)" ;
VAL_ 532 BMSH_BatUseableSOC 1022 "Abnormal(异常)" 1023 "Invalid(无效)" ;
VAL_ 532 BMSH_BatRealSOC 1022 "Abnormal(异常)" 1023 "Invalid(无效)" ;
VAL_ 532 BMSH_BatSOH 1022 "Abnormal(异常)" 1023 "Invalid(无效)" ;
VAL_ 532 BMSH_BatSOE 16382 "Abnormal(异常)" 16383 "Invalid(无效)" ;
VAL_ 186 BMSH_PackVolt 65534 "Abnormity(异常)" 65535 "Invalid(无效)" ;
VAL_ 186 BMSH_BusVolt 65534 "Abnormity(异常)" 65535 "Invalid(无效)" ;
VAL_ 186 BMSH_BatCurrent 65534 "Abnormity(异常)" 65535 "Invalid(无效)" ;
VAL_ 534 BMSH_TBOX_CellVoltMaxID 255 "Invalid(无效)" ;
VAL_ 534 BMSH_TBOX_CellVoltMinID 255 "Invalid(无效)" ;
VAL_ 534 BMSH_CellVoltMaxModuleID 255 "Invalid(无效)" ;
VAL_ 534 BMSH_CellVoltMinModuleID 255 "Invalid(无效)" ;
VAL_ 903 BMSH_TBOX_MaxTempID 255 "Invalid(无效)" ;
VAL_ 903 BMSH_TBOX_MinTempID 255 "Invalid(无效)" ;
VAL_ 903 BMSH_BatTempMax 255 "Invalid(无效)" ;
VAL_ 903 BMSH_BatTempMin 255 "Invalid(无效)" ;
VAL_ 903 BMSH_BatTempAvg 255 "Invalid(无效)" ;
VAL_ 535 BMSH_CCM_LiquidInTemp 255 "BMSH 进水口温度传感器故障" ;
VAL_ 535 BMSH_CCM_LiquidOutTemp 255 "BMSH 出水口温度传感器故障" ;
VAL_ 535 BMSH_CCM_ThermalManageReq 0 "No require(无请求)" 1 "Heating(加热)" 2 "Cooling(冷却)" 3 "Balance(匀热)" 4 "Invalid(无效)" ;
VAL_ 537 BMSH_OBC_StsModeReq 2 "Standby(待机)" 7 "DisCharge(对外放电）" 9 "Heating/Cooling(热管理)" 10 "Charge allowed(允许充电)" 11 "ShutDown(关闭)" ;
VAL_ 543 BMSH_DCChargeProcess 0 "Defult(默认)" 1 "DC Preparing(充电准备中)" 2 "DC Charging(充电中)" 3 "DC Charged(充电完成)" ;
VAL_ 543 BMSH_DCChgEnder 0 "Defult(默认)" 1 "BMSH(电池端)" 2 "Pile(充电桩)" 3 "Reserved(保留)" ;
VAL_ 543 BMSH_DCChgStandVer 0 "Defult(默认)" 1 "2011版" 2 "2015版" ;
VAL_ 543 BMSH_DCChgCurReq 255 "Invalid(无效)" ;
VAL_ 543 BMSH_DCEquipment_DisplayCur 255 "Invalid(无效)" ;
VAL_ 904 BMSH_ChgOverCurrent 0 "Normal(正常)" 1 "Fault Level I(1级故障)" 2 "Fault Level II(2级故障)" 3 "Fault Level III(3级故障)" ;
VAL_ 904 BMSH_DisChgOverCurrent 0 "Normal(正常)" 1 "Fault Level I(1级故障)" 2 "Fault Level II(2级故障)" 3 "Fault Level III(3级故障)" ;
VAL_ 904 BMSH_CellOverVolt 0 "Normal(正常)" 1 "Fault Level I(1级故障)" 2 "Fault Level II(2级故障)" 3 "Fault Level III(3级故障)" ;
VAL_ 904 BMSH_CellUnderVolt 0 "Normal(正常)" 1 "Fault Level I(1级故障)" 2 "Fault Level II(2级故障)" 3 "Fault Level III(3级故障)" ;
VAL_ 904 BMSH_ChgOverTemp 0 "Normal(正常)" 1 "Fault Level I(1级故障)" 2 "Fault Level II(2级故障)" 3 "Fault Level III(3级故障)" ;
VAL_ 904 BMSH_BatUnderVolt 0 "Normal(正常)" 1 "Fault Level I(1级故障)" 2 "Fault Level II(2级故障)" 3 "Fault Level III(3级故障)" ;
VAL_ 904 BMSH_BatOverVolt 0 "Normal(正常)" 1 "Fault Level I(1级故障)" 2 "Fault Level II(2级故障)" 3 "Fault Level III(3级故障)" ;
VAL_ 904 BMSH_CellDiffVoltUniform 0 "Normal(正常)" 1 "Fault Level I(1级故障)" 2 "Fault Level II(2级故障)" 3 "Fault Level III(3级故障)" ;
VAL_ 904 BMSH_CellTempUniformity 0 "Normal(正常)" 1 "Fault Level I(1级故障)" 2 "Fault Level II(2级故障)" 3 "Fault Level III(3级故障)" ;
VAL_ 904 BMSH_DisChgUnderTemp 0 "Normal(正常)" 1 "Fault Level I(1级故障)" 2 "Fault Level II(2级故障)" 3 "Fault Level III(3级故障)" ;
VAL_ 904 BMSH_DisChgOverTemp 0 "Normal(正常)" 1 "Fault Level I(1级故障)" 2 "Fault Level II(2级故障)" 3 "Fault Level III(3级故障)" ;
VAL_ 904 BMSH_ChgUnderTemp 0 "Normal(正常)" 1 "Fault Level I(1级故障)" 2 "Fault Level II(2级故障)" 3 "Fault Level III(3级故障)" ;
VAL_ 904 BMSH_MainPosRelayFault 0 "Normal(正常)" 1 "Can not close(不能关)" 2 "Can not open(不能开)" 3 "Invalid(无效)" ;
VAL_ 904 BMSH_RecoveryOverCurrent 0 "Normal(正常)" 1 "Fault Level I(1级故障)" 2 "Fault Level II(2级故障)" 3 "Fault Level III(3级故障)" ;
VAL_ 904 BMSH_BatUnderSOC 0 "Normal(正常)" 1 "Fault Level I(1级故障)" 2 "Fault Level II(2级故障)" 3 "Fault Level III(3级故障)" ;
VAL_ 904 BMSH_BatOverSOC 0 "Normal(正常)" 1 "Fault Level I(1级故障)" 2 "Fault Level II(2级故障)" 3 "Fault Level III(3级故障)" ;
VAL_ 904 BMSH_DCChgPlugNOverTemp 0 "Normal(正常)" 1 "Risk (温度偏高)" 2 "Error(温度过高)" 3 "Invalid(无效)" ;
VAL_ 904 BMSH_DCChgPlugPOverTemp 0 "Normal(正常)" 1 "Risk (温度偏高)" 2 "Error(温度过高)" 3 "Invalid(无效)" ;
VAL_ 904 BMSH_DCChgRelayFault 0 "Normal(正常)" 1 "Can not close(不能关)" 2 "Can not open(不能开)" 3 "Invalid(无效)" ;
VAL_ 904 BMSH_MainNegRelayFault 0 "Normal(正常)" 1 "Can not close(不能关)" 2 "Can not open(不能开)" 3 "Invalid(无效)" ;
VAL_ 904 BMSH_IntComFault 0 "Normal(正常)" 1 "Error(异常)" ;
VAL_ 904 BMSH_DisChgComFault 0 "Normal(正常)" 1 "Error(异常)" ;
VAL_ 904 BMSH_FastChgComFault 0 "Normal(正常)" 1 "Error(异常)" ;
VAL_ 904 BMSH_12VBatFault 0 "Normal(正常)" 1 "Error(异常)" ;
VAL_ 904 BMSH_ConnectPosOverTemp 0 "Normal(正常)" 1 "Risk (温度偏高)" 2 "Error(温度过高)" 3 "Invalid(无效)" ;
VAL_ 904 BMSH_ConnectNegOverTemp 0 "Normal(正常)" 1 "Risk (温度偏高)" 2 "Error(温度过高)" 3 "Invalid(无效)" ;
VAL_ 904 BMSH_VCUChksumFault 0 "Normal(正常)" 1 "Error(异常)" ;
VAL_ 904 BMSH_VCURollCountFault 0 "Normal(正常)" 1 "Error(异常)" ;
VAL_ 904 BMSH_OBCChksumFault 0 "Normal(正常)" 1 "Error(异常)" ;
VAL_ 904 BMSH_OBCRollCountFault 0 "Normal(正常)" 1 "Error(异常)" ;
VAL_ 904 BMSH_SelfCheckFault 0 "Normal(正常)" 1 "Error(异常)" ;
VAL_ 904 BMSH_DataStorageFault 0 "Normal(正常)" 1 "Error(异常)" ;
VAL_ 909 BMSH_TBOX_BatProductMonth 0 "Invalid(无效)" ;
VAL_ 909 BMSH_TBOX_BatProductDay 0 "Invalid(无效)" ;
VAL_ 910 BMSH_TBOX_BatSeriesCellsSum 254 "Fault(错误值)" 255 "Invalid(无效值)" ;
VAL_ 910 BMSH_TBOX_BatModuleSum 255 "Invalid(无效值)" ;
VAL_ 910 BMSH_TBOX_CellsSum 65533 "Fault(错误值)" 65535 "Invalid(无效值)" ;
VAL_ 911 BMSH_TBOX_BatType 1 "磷酸铁锂电池" 2 "锰酸锂电池" 3 "钴酸锂电池" 4 "三元材料电池" 5 "聚合物锂离子电池" 6 "超级电容" 7 "钛酸锂电池" 252 "燃料电池" 255 "其他车载储能装置" ;
VAL_ 538 BMSH_TBOX_CellA_ID 255 "Invalid(无效)" ;
VAL_ 539 BMSH_TBOX_TempA_ID 255 "Invalid(无效)" ;
VAL_ 905 BMSH_TBOX_BatFaultList 255 "Invaid(无效)" ;
VAL_ 905 BMSH_TBOX_BatOverTemp 0 "Normal(正常)" 1 "Error(异常)" ;
VAL_ 905 BMSH_TBOX_BatLowTemp 0 "Normal(正常)" 1 "Error(异常)" ;
VAL_ 905 BMSH_TBOX_BatOverVoltage 0 "Normal(正常)" 1 "Error(异常)" ;
VAL_ 905 BMSH_TBOX_BatUnderVoltage 0 "Normal(正常)" 1 "Error(异常)" ;
VAL_ 905 BMSH_TBOX_BatStoreSysFault 0 "Normal(正常)" 1 "Error(异常)" ;
VAL_ 905 BMSH_TBOX_BatIsoAlarm 0 "Normal(正常)" 1 "Error(异常)" ;
VAL_ 905 BMSH_TBOX_BatHVILFault 0 "Normal(正常)" 1 "Error(异常)" ;
VAL_ 905 BMSH_TBOX_BatMismatching 0 "Normal(正常)" 1 "Error(异常)" ;
VAL_ 905 BMSH_TBOX_CellOverVoltage 0 "Normal(正常)" 1 "Error(异常)" ;
VAL_ 905 BMSH_TBOX_CellUnderVoltage 0 "Normal(正常)" 1 "Error(异常)" ;
VAL_ 905 BMSH_TBOX_BatUniformity 0 "Normal(正常)" 1 "Error(异常)" ;
VAL_ 905 BMSH_TBOX_BatOverCharge 0 "Normal(正常)" 1 "Error(异常)" ;
VAL_ 905 BMSH_TBOX_SOCHop 0 "Normal(正常)" 1 "Error(异常)" ;
VAL_ 905 BMSH_TBOX_BatOverSOC 0 "Normal(正常)" 1 "Error(异常)" ;
VAL_ 905 BMSH_TBOX_BatLowSOC 0 "Normal(正常)" 1 "Error(异常)" ;
VAL_ 905 BMSH_TBOX_BatTempUniformity 0 "Normal(正常)" 1 "Error(异常)" ;
VAL_ 905 BMSH_DCChgRx_OTime_CSD 0 "Normal(正常)" 1 "Error(异常)" ;
VAL_ 905 BMSH_DCChgRx_OTime_CCS 0 "Normal(正常)" 1 "Error(异常)" ;
VAL_ 905 BMSH_DCChgRx_OTime_CROAA 0 "Normal(正常)" 1 "Error(异常)" ;
VAL_ 905 BMSH_DCChgRx_OTime_CRO00 0 "Normal(正常)" 1 "Error(异常)" ;
VAL_ 905 BMSH_DCChgRx_OTime_CML 0 "Normal(正常)" 1 "Error(异常)" ;
VAL_ 905 BMSH_DCChgRx_OTime_CRMAA 0 "Normal(正常)" 1 "Error(异常)" ;
VAL_ 905 BMSH_DCChgRx_OTime_CRM00 0 "Normal(正常)" 1 "Error(异常)" ;
VAL_ 662 DCDC_StsCtrl 0 "Inactive(不工作)" 1 "Buck(降压)" 2 "Bost(升压)(预留)" 3 "Active Discharge(主动放电)(预留)" ;
VAL_ 662 DCDC_StsDCDCFault 0 "Normal(正常)" 1 "Derating(降功率)" 2 "Shutdown(关机)" 3 "Invalid(无效)" ;
VAL_ 663 DCDC_OutHWOpen 0 "Normal(正常)" 1 "Error(异常)" ;
VAL_ 663 DCDC_OutHWVoltOver 0 "Normal(正常)" 1 "Error(异常)" ;
VAL_ 663 DCDC_VCU_OverTemp 0 "Normal(正常)" 1 "OverTemp Level I(1级故障降功率)" 2 "OverTemp Level II(2级故障禁止充电)" 3 "Reserved(预留)" ;
VAL_ 663 DCDC_HWFault 0 "Normal(正常)" 1 "Error(异常)" ;
VAL_ 663 DCDC_OutPwrOver 0 "Normal(正常)" 1 "Error(异常)" ;
VAL_ 663 DCDC_OutCurOver 0 "Normal(正常)" 1 "Error(异常)" ;
VAL_ 663 DCDC_OutVoltOver 0 "Normal(正常)" 1 "Error(异常)" ;
VAL_ 663 DCDC_OutVoltUnder 0 "Normal(正常)" 1 "Error(异常)" ;
VAL_ 663 DCDC_InVoltOver 0 "Normal(正常)" 1 "Error(异常)" ;
VAL_ 663 DCDC_InVoltUnder 0 "Normal(正常)" 1 "Error(异常)" ;
VAL_ 663 DCDC_OutCircuitShort 0 "Normal(正常)" 1 "Error(异常)" ;
VAL_ 663 DCDC_VCULostFault 0 "Normal(正常)" 1 "Error(异常)" ;
VAL_ 663 DCDC_CANBusoffFault 0 "Normal(正常)" 1 "Error(异常)" ;
VAL_ 663 DCDC_WakeupInMissing 0 "Normal(正常)" 1 "Error(异常)" ;
VAL_ 663 DCDC_12VFault 0 "Normal(正常)" 1 "Error(异常)" ;
VAL_ 201 IPU_VCU_IPUFaultReq 0 "Init(初始化)" 1 "Normal(正常)" 5 "Derating(降功率)" 7 "Limphome(跛行回家)" 9 "ZeroTorque(零扭矩)" 11 "Powerdown(延迟下电)" 15 "Invalid(无效)" ;
VAL_ 201 IPU_StsIPUFault 0 "Normal(正常)" 3 "Warning(报警)" 5 "Derating(降功率)" 7 "Limphome(跛行回家)" 9 "ZeroTorque(零扭矩)" 11 "Powerdown(延迟下电)" 12 "emPowerdown(紧急下电)" 15 "Invalid(无效)" ;
VAL_ 201 IPU_VCU_CtrlMode 0 "Inactive(无输出)" 1 "Torque control mode(扭矩控制)" 2 "Anti-slideSlope(防溜坡)" 3 "Reserved(预留)" ;
VAL_ 201 IPU_VCU_StsMode 0 "Default(默认值)" 1 "Init(初始化)" 2 "Standby(待机)" 3 "Precharge (预充)" 4 "Normal(正常运行)" 11 "ShutDown(关闭)" 12 "AfterRun(运行后)" 14 "PowerOff(下电)" 15 "Invalid(无效)" ;
VAL_ 201 IPU_MotorTq 65534 "Abnormal(异常)" 65535 "Invalid(无效)" ;
VAL_ 201 IPU_MotorSpd 65534 "Abnormal(异常)" 65535 "Invalid(无效)" ;
VAL_ 201 IPU_ReleaseSig 0 "Undefined(默认)" 1 "Released(动力系统认证释放)" 2 "Locked(动力系统认证锁止)" 3 "Reserved(预留)??" ;
VAL_ 201 IPU_MotorSpdInvalid 0 "Valid(有效)" 1 "Invalid(无效)" ;
VAL_ 201 IPU_MotorTqInvalid 0 "Valid(有效)" 1 "Invalid(无效)" ;
VAL_ 871 IPU_IPUTemp 254 "Abnormal(异常)" 255 "Invalid(无效)" ;
VAL_ 871 IPU_MotorTemp 254 "Abnormal(异常)" 255 "Invalid(无效)" ;
VAL_ 872 IPU_TheftFault 0 "Normal(正常)" 1 "Error(异常)" ;
VAL_ 872 IPU_NoESK 0 "Normal(正常)" 1 "Error(异常)" ;
VAL_ 872 IPU_InitMode 0 "Normal(正常)" 1 "Error(异常)" ;
VAL_ 872 IPU_IPUCurrentSenVZeroFault 0 "Normal(正常)" 1 "Error(异常)" ;
VAL_ 872 IPU_IPUCurrentSenUZeroFault 0 "Normal(正常)" 1 "Error(异常)" ;
VAL_ 872 IPU_MotTempSenVFault 0 "Normal(正常)" 1 "Error(异常)" ;
VAL_ 872 IPU_MotTempSenWFault 0 "Normal(正常)" 1 "Error(异常)" ;
VAL_ 872 IPU_PhaseOverCurrentSWFault 0 "Normal(正常)" 1 "Error(异常)" ;
VAL_ 872 IPU_IPUOverTempFault 0 "Normal(正常)" 1 "Error(异常)" ;
VAL_ 872 IPU_IPUOverTempAlarm 0 "Normal(正常)" 1 "Error(异常)" ;
VAL_ 872 IPU_MotTempSenUFault 0 "Normal(正常)" 1 "Error(异常)" ;
VAL_ 872 IPU_MotTempSenFault 0 "Normal(正常)" 1 "Error(异常)" ;
VAL_ 872 IPU_MotOverTempFault 0 "Normal(正常)" 1 "Error(异常)" ;
VAL_ 872 IPU_MotOverTempAlarm 0 "Normal(正常)" 1 "Error(异常)" ;
VAL_ 872 IPU_HVUnderVoltage2 0 "Normal(正常)" 1 "Error(异常)" ;
VAL_ 872 IPU_HVUnderVoltage1 0 "Normal(正常)" 1 "Error(异常)" ;
VAL_ 872 IPU_HVOverVoltage2 0 "Normal(正常)" 1 "Error(异常)" ;
VAL_ 872 IPU_HVOverVoltage1 0 "Normal(正常)" 1 "Error(异常)" ;
VAL_ 872 IPU_IPUCPhsSenRatFault 0 "Normal(正常)" 1 "Error(异常)" ;
VAL_ 872 IPU_IPUAPhsSenRatFault 0 "Normal(正常)" 1 "Error(异常)" ;
VAL_ 872 IPU_PhaseOverCurrentHWFault 0 "Normal(正常)" 1 "Error(异常)" ;
VAL_ 872 IPU_MotOverSpd2 0 "Normal(正常)" 1 "Error(异常)" ;
VAL_ 872 IPU_MotOverSpd1 0 "Normal(正常)" 1 "Error(异常)" ;
VAL_ 872 IPU_12VUnderVoltageAlarm 0 "Normal(正常)" 1 "Error(异常)" ;
VAL_ 872 IPU_12VOverVoltageAlarm 0 "Normal(正常)" 1 "Error(异常)" ;
VAL_ 872 IPU_IPUHVSensorFault 0 "Normal(正常)" 1 "Error(异常)" ;
VAL_ 872 IPU_IPUDisChgFault 0 "Normal(正常)" 1 "Error(异常)" ;
VAL_ 872 IPU_IPUEnableFault 0 "Normal(正常)" 1 "Error(异常)" ;
VAL_ 872 IPU_MotTrqChksumFault 0 "Normal(正常)" 1 "Error(异常)" ;
VAL_ 872 IPU_MotTrqLimFault 0 "Normal(正常)" 1 "Error(异常)" ;
VAL_ 872 IPU_MotTrqFault 0 "Normal(正常)" 1 "Error(异常)" ;
VAL_ 872 IPU_IPUBlockedFault 0 "Normal(正常)" 1 "Error(异常)" ;
VAL_ 872 IPU_MotRotSenFault 0 "Normal(正常)" 1 "Error(异常)" ;
VAL_ 872 IPU_BMSHLostFault 0 "Normal(正常)" 1 "Error(异常)" ;
VAL_ 872 IPU_VCULostFault 0 "Normal(正常)" 1 "Error(异常)" ;
VAL_ 872 IPU_CANBusoffFault 0 "Normal(正常)" 1 "Error(异常)" ;
VAL_ 872 IPU_IGBTDrvPwrFault 0 "Normal(正常)" 1 "Error(异常)" ;
VAL_ 873 IPU_TBOX_FaultAmount 255 "Invalid(无效)" ;
VAL_ 873 IPU_TBOX_FaultList 255 "Invalid(无效)" ;
VAL_ 873 IPU_StsActiveDischg 0 "No Active Discharge" 1 "Active Discharge" 2 "Failed Active Discharge" 3 "Finished Active Discharge" ;
VAL_ 873 IPU_TBOX_ModeMotorDrv 1 "DispateEnergy(耗电)" 2 "GenerateEnergy(发电)" 3 "Shutdown(关闭)" 4 "Ready(准备状态)" 348175 "Reserved(预留)" ;
VAL_ 873 IPU_MotorTempV 0 "Normal(正常)" 1 "Error(异常)" ;
VAL_ 694 OBC_StsMode 0 "Default(默认值)" 1 "Init(初始化)" 2 "Standby(待机)" 5 "Slow Charge(慢充)" 7 "DisCharge(对外放电)" 9 "Heating/Cooling(热管理)" 11 "ShutDown(关闭)" 12 "AfterRun(运行后)" 13 "End of charge(充电完成)(预留)" 14 "PowerOff(下电)" 15 "Invalid(无效)" ;
VAL_ 694 OBC_BMSH_ChgFaultReq 0 "Normal(正常)" 2 "Derating(降功率)" 3 "Recover Prohibit Charge" 6 "Powerdown(下高压)" ;
VAL_ 694 OBC_StsCP 7 "Invalid(无效)" 0 "CP open(V=0V)(CP断开)" 1 "S2 open(V=9V)(S2断开)" 2 "Connect with Power(V=6V)(充电许可)" 3 "S2 Signal Fault(S2信号错误)" 4 "CP Signal Fault(CP信号错误)" ;
VAL_ 694 OBC_StsChgCC 0 "CC open(CC断开)" 1 "Charge Connect(充电连接)" 2 "Half Connect(S3断开)" 3 "Signal Fault(信号错误)" ;
VAL_ 694 OBC_BMSH_PWMCP 255 "Invalid(无效)" ;
VAL_ 694 OBC_StsElock 0 "Unlock(未锁)" 1 "Lock(锁止)" 2 "Lock Fault(锁故障)" 3 "Invalid(无效)" ;
VAL_ 919 OBC_OBCTemp 255 "Invalid(无效)" ;
VAL_ 919 OBC_BMSH_NTerminalOverTemp 0 "Normal(正常)" 1 "OverTemp Level I(1级故障降功率)" 2 "OverTemp Level II(2级故障禁止充电)" 3 "Reserved(预留)" ;
VAL_ 919 OBC_BMSH_LTerminalOverTemp 0 "Normal(正常)" 1 "OverTemp Level I(1级故障降功率)" 2 "OverTemp Level II(2级故障禁止充电)" 3 "Reserved(预留)" ;
VAL_ 919 OBC_InletTempSenFault 0 "Normal(正常)" 1 "Error(异常)" ;
VAL_ 920 OBC_InputACinterrupt 0 "Normal(正常)" 1 "Error(异常)" ;
VAL_ 920 OBC_InputOverCurrent 0 "Normal(正常)" 1 "Error(异常)" ;
VAL_ 920 OBC_InputOverVoltage 0 "Normal(正常)" 1 "Error(异常)" ;
VAL_ 920 OBC_InputUnderVoltage 0 "Normal(正常)" 1 "Error(异常)" ;
VAL_ 920 OBC_12VFault 0 "Normal(正常)" 1 "Error(异常)" ;
VAL_ 920 OBC_S2ControlFault 0 "Normal(正常)" 1 "Error(异常)" ;
VAL_ 920 OBC_OverTemp 0 "Normal(正常)" 1 "OverTemp Level I(1级故障降功率)" 2 "OverTemp Level II(2级故障禁止充电)" 3 "Reserved" ;
VAL_ 920 OBC_ComTimeOut 0 "Normal(正常)" 1 "Error(异常)" ;
VAL_ 920 OBC_WakeUpInputMiss 0 "Normal(正常)" 1 "Error(异常)" ;
VAL_ 920 OBC_BatteryVoltageFault 0 "Normal(正常)" 1 "Error(异常)" ;
VAL_ 920 OBC_OutputInversed 0 "Normal(正常)" 1 "Error(异常)" ;
VAL_ 920 OBC_OutputShortCircuit 0 "Normal(正常)" 1 "Error(异常)" ;
VAL_ 920 OBC_OutputOverCurrent 0 "Normal(正常)" 1 "Error(异常)" ;
VAL_ 920 OBC_OutputOverVoltage 0 "Normal(正常)" 1 "Error(异常)" ;
VAL_ 920 OBC_OutputUnderVoltage 0 "Normal(正常)" 1 "Error(异常)" ;
VAL_ 920 OBC_InternalComFault 0 "Normal(正常)" 1 "Error(异常)" ;
VAL_ 920 OBC_DataStorageFault 0 "Normal(正常)" 1 "Error(异常)" ;
VAL_ 920 OBC_HWFault 0 "Normal(正常)" 1 "Error(异常)" ;
VAL_ 920 OBC_ComMissing 0 "Normal(正常)" 1 "Error(异常)" ;
